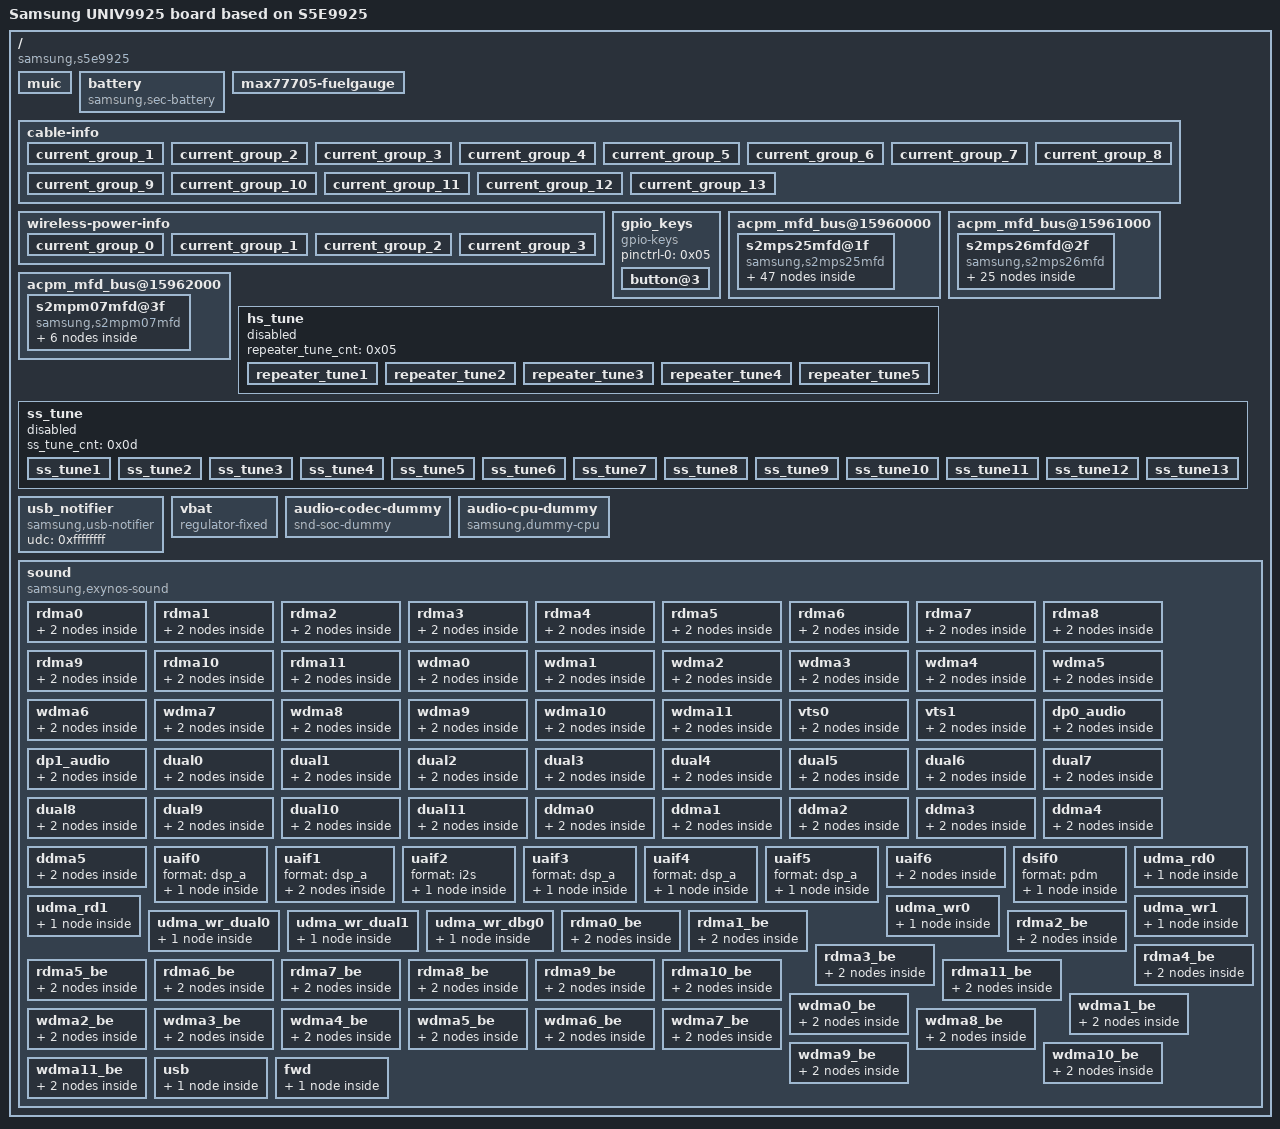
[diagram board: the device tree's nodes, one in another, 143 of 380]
/dts-v1/;

/ {
	compatible = "samsung,s5e9925\0samsung,UNIV9925";
	board_id = <0x01>;
	board_rev = <0x1b>;

	fragment@muic {
		target-path = "/";

		__overlay__ {

			muic {
				status = "okay";
				muic,support-list = "TA\0USB\0CDP\0JIG UART OFF\0JIG UART OFF/VB\0JIG UART ON\0JIG UART ON/VB\0JIG USB OFF\0JIG USB ON\0OTG\0Unofficial TA\0DCD Timeout\0AFC Charger";
			};
		};
	};

	fragment@0 {
		target = <0xffffffff>;

		__overlay__ {

			max77705-irq {
				samsung,pins = "gpa0-0";
				samsung,pin-function = <0x0f>;
				samsung,pin-pud = <0x00>;
				samsung,pin-drv = <0x00>;
				phandle = <0x02>;
			};
		};
	};

	fragment@1 {
		target = <0xffffffff>;

		__overlay__ {

			hsi2c2-bus-max77705 {
				samsung,pins = "gpm0-0\0gpm0-1";
				samsung,pin-function = <0x02>;
				samsung,pin-pud = <0x00>;
				samsung,pin-drv = <0x00>;
				samsung,pin-con-pdn = <0x03>;
				samsung,pin-pud-pdn = <0x00>;
				phandle = <0x01>;
			};
		};
	};

	fragment@2 {
		target = <0xffffffff>;

		__overlay__ {
			#address-cells = <0x01>;
			#size-cells = <0x00>;
			status = "okay";
			pinctrl-0 = <0x01>;

			max77705@66 {
				compatible = "maxim,max77705";
				pinctrl-names = "default";
				pinctrl-0 = <0x02>;
				reg = <0x66>;
				max77705,irq-gpio = <0xffffffff 0x00 0x01>;
				max77705,wakeup;
				max77705,fw_product_id = <0x03>;
				max77705,support-audio;
				phandle = <0x1d>;

				max77705_pdic {
					status = "okay";
					compatible = "maxim,max77705_pdic";
					support_pd_role_swap;
				};
			};
		};
	};

	fragment@battery {
		target-path = "/";

		__overlay__ {

			battery {
				status = "okay";
				compatible = "samsung,sec-battery";
				pinctrl-names = "default";
				battery,vendor = "Battery";
				battery,charger_name = "max77705-charger";
				battery,fuelgauge_name = "max77705-fuelgauge";
				battery,technology = <0x02>;
				battery,fgsrc_switch_name = "max77705-charger";
				battery,batt_data_version = <0x03>;
				battery,chip_vendor = "LSI";
				battery,temp_adc_type = <0x01>;
				battery,temp_check_type = <0x03>;
				battery,usb_temp_check_type = <0x03>;
				battery,chg_temp_check_type = <0x03>;
				battery,wpc_temp_check_type = <0x03>;
				battery,dchg_temp_check_type = <0x03>;
				battery,thermal_source = <0x02>;
				battery,usb_thermal_source = <0x02>;
				battery,chg_thermal_source = <0x02>;
				battery,wpc_thermal_source = <0x02>;
				battery,dchg_thermal_source = <0x03>;
				battery,polling_time = <0x0a 0x1e 0x1e 0x1e 0xe10>;
				battery,temp_table_adc = <0x137 0x168 0x1a0 0x1e3 0x232 0x28f 0x2fb 0x379 0x409 0x48a 0x53c 0x603 0x6da 0x7ba 0x8ab 0x99b 0xa8a 0xb6a 0xc33 0xce8 0xd89 0xe04 0xe5f>;
				battery,temp_table_data = <0x384 0x352 0x320 0x2ee 0x2bc 0x28a 0x258 0x226 0x1f4 0x1c2 0x190 0x15e 0x12c 0xfa 0xc8 0x96 0x64 0x32 0x00 0xffffffce 0xffffff9c 0xffffff6a 0xffffff38>;
				battery,usb_temp_table_adc = <0x10c 0x146 0x180 0x1c5 0x214 0x270 0x2dd 0x35b 0x3e9 0x489 0x54c 0x616 0x6ee 0x7d0 0x8bb 0x9a6 0xa84 0xb61 0xc1c 0xcce 0xd67 0xdd3 0xe51>;
				battery,usb_temp_table_data = <0x384 0x352 0x320 0x2ee 0x2bc 0x28a 0x258 0x226 0x1f4 0x1c2 0x190 0x15e 0x12c 0xfa 0xc8 0x96 0x64 0x32 0x00 0xffffffce 0xffffff9c 0xffffff6a 0xffffff38>;
				battery,chg_temp_table_adc = <0xdd 0x114 0x14b 0x18e 0x1da 0x234 0x29b 0x31a 0x3a7 0x448 0x505 0x5d1 0x6af 0x799 0x889 0x97c 0xa69 0xb4f 0xc1f 0xcdb 0xd76 0xdf0 0xe75>;
				battery,chg_temp_table_data = <0x384 0x352 0x320 0x2ee 0x2bc 0x28a 0x258 0x226 0x1f4 0x1c2 0x190 0x15e 0x12c 0xfa 0xc8 0x96 0x64 0x32 0x00 0xffffffce 0xffffff9c 0xffffff6a 0xffffff38>;
				battery,wpc_temp_table_adc = <0x137 0x168 0x1a0 0x1e3 0x232 0x28f 0x2fb 0x379 0x409 0x48a 0x53c 0x603 0x6da 0x7ba 0x8ab 0x99b 0xa8a 0xb6a 0xc33 0xce8 0xd89 0xe04 0xe5f>;
				battery,wpc_temp_table_data = <0x384 0x352 0x320 0x2ee 0x2bc 0x28a 0x258 0x226 0x1f4 0x1c2 0x190 0x15e 0x12c 0xfa 0xc8 0x96 0x64 0x32 0x00 0xffffffce 0xffffff9c 0xffffff6a 0xffffff38>;
				battery,dchg_temp_table_adc = <0x15c3c 0x1b7e0 0x21384 0x2817c 0x301c8 0x39d92 0x454da 0x527a0 0x61f0e 0x731fa 0x86064 0x9c5ca 0xb3d84 0xcd9e6 0xe7648 0x1024fe 0x11c160 0x134b6e 0x14b9fe 0x15fabc 0x170da8 0x17f2c2 0x18b334>;
				battery,dchg_temp_table_data = <0x384 0x352 0x320 0x2ee 0x2bc 0x28a 0x258 0x226 0x1f4 0x1c2 0x190 0x15e 0x12c 0xfa 0xc8 0x96 0x64 0x32 0x00 0xffffffce 0xffffff9c 0xffffff6a 0xffffff38>;
				battery,wireless_cc_cv = <0x55>;
				battery,wpc_cc_cv_vout = <0x157c>;
				battery,wpc_cv_call_vout = <0x1388>;
				battery,wpc_cc_call_vout = <0x1388>;
				battery,wpc_det = <0xffffffff 0x00 0x00>;
				battery,wpc_int = <0xffffffff 0x01 0x00>;
				battery,hv_vout_wa = <0x41>;
				battery,adc_check_count = <0x05>;
				battery,cable_check_type = <0x04>;
				battery,cable_source_type = <0x01>;
				battery,polling_type = <0x01>;
				battery,monitor_initial_count = <0x00>;
				battery,battery_check_type = <0x00>;
				battery,check_count = <0x00>;
				battery,check_adc_max = <0x5a0>;
				battery,check_adc_min = <0x00>;
				battery,ovp_uvlo_check_type = <0x03>;
				battery,temp_check_count = <0x01>;
				battery,overheatlimit_threshold = <0x2bc>;
				battery,overheatlimit_recovery = <0x2a8>;
				battery,wire_warm_overheat_thresh = <0x1f4>;
				battery,wire_normal_warm_thresh = <0x19a>;
				battery,wire_cool1_normal_thresh = <0xb4>;
				battery,wire_cool2_cool1_thresh = <0x96>;
				battery,wire_cool3_cool2_thresh = <0x32>;
				battery,wire_cold_cool3_thresh = <0x00>;
				battery,wireless_warm_overheat_thresh = <0x1c2>;
				battery,wireless_normal_warm_thresh = <0x19a>;
				battery,wireless_cool1_normal_thresh = <0xb4>;
				battery,wireless_cool2_cool1_thresh = <0x96>;
				battery,wireless_cool3_cool2_thresh = <0x32>;
				battery,wireless_cold_cool3_thresh = <0x00>;
				battery,wire_warm_current = <0x625>;
				battery,wire_cool1_current = <0xc4a>;
				battery,wire_cool2_current = <0x418>;
				battery,wire_cool3_current = <0x1b5>;
				battery,wireless_warm_current = <0x418>;
				battery,wireless_cool1_current = <0xc4a>;
				battery,wireless_cool2_current = <0x418>;
				battery,wireless_cool3_current = <0x1b5>;
				battery,tx_high_threshold = <0x1c2>;
				battery,tx_high_recovery = <0x190>;
				battery,tx_low_threshold = <0x00>;
				battery,tx_low_recovery = <0x32>;
				battery,full_check_type = <0x02>;
				battery,full_check_type_2nd = <0x02>;
				battery,full_check_count = <0x01>;
				battery,chg_gpio_full_check = <0x00>;
				battery,chg_polarity_full_check = <0x01>;
				battery,chg_high_temp = <0x1d6>;
				battery,chg_high_temp_recovery = <0x1c2>;
				battery,dchg_high_temp = <0x208>;
				battery,dchg_high_temp_recovery = <0x1cc>;
				battery,dchg_high_batt_temp = <0x190>;
				battery,dchg_high_batt_temp_recovery = <0x17c>;
				battery,chg_input_limit_current = <0x3e8>;
				battery,chg_charging_limit_current = <0x76c>;
				battery,dchg_input_limit_current = <0x3e8>;
				battery,dchg_charging_limit_current = <0x7d0>;
				battery,charging_limit_by_tx_check = <0x01>;
				battery,charging_limit_current_by_tx = <0x4b0>;
				battery,wpc_temp_control_source = <0x01>;
				battery,wpc_high_temp = <0x190>;
				battery,wpc_high_temp_recovery = <0x17c>;
				battery,wpc_input_limit_current = <0x258>;
				battery,wpc_charging_limit_current = <0x3e8>;
				battery,wpc_temp_lcd_on_control_source = <0x01>;
				battery,wpc_lcd_on_high_temp = <0x190>;
				battery,wpc_lcd_on_high_temp_rec = <0x17c>;
				battery,wpc_lcd_on_input_limit_current = <0x1c2>;
				battery,wpc_store_high_temp = <0x168>;
				battery,wpc_store_high_temp_recovery = <0x154>;
				battery,wpc_store_lcd_on_high_temp = <0x168>;
				battery,wpc_store_lcd_on_high_temp_rec = <0x12c>;
				battery,wpc_store_lcd_on_charging_limit_current = <0x190>;
				battery,sleep_mode_limit_current = <0x320>;
				battery,wc_full_input_limit_current = <0x64>;
				battery,mix_high_temp = <0x1a4>;
				battery,mix_high_chg_temp = <0x1f4>;
				battery,mix_high_dc_temp = <0x244>;
				battery,mix_high_temp_recovery = <0x186>;
				battery,full_condition_type = <0x09>;
				battery,full_condition_soc = <0x5d>;
				battery,full_condition_vcell = <0x10ea>;
				battery,recharge_check_count = <0x01>;
				battery,recharge_condition_type = <0x04>;
				battery,recharge_condition_soc = <0x62>;
				battery,recharge_condition_vcell = <0x10d6>;
				battery,charging_total_time = <0x3840>;
				battery,hv_charging_total_time = <0x2a30>;
				battery,normal_charging_total_time = <0x4650>;
				battery,usb_charging_total_time = <0x8ca0>;
				battery,recharging_total_time = <0x1518>;
				battery,charging_reset_time = <0x00>;
				battery,chg_float_voltage = <0x111c>;
				battery,chg_ocp_current = <0x1838>;
				battery,chg_ocp_dtc = <0x64>;
				battery,swelling_drop_float_voltage = <0x1036>;
				battery,swelling_high_rechg_voltage = <0xfa0>;
				battery,swelling_low_rechg_voltage = <0xfa0>;
				battery,wa_float_voltage = <0xfd2>;
				battery,siop_event_check_type = <0x01>;
				battery,siop_call_cv_current = <0x12c>;
				battery,siop_call_cc_current = <0x12c>;
				battery,siop_input_limit_current = <0x4b0>;
				battery,siop_charging_limit_current = <0x3e8>;
				battery,siop_hv_input_limit_current = <0x2bc>;
				battery,siop_hv_charging_limit_current = <0x3e8>;
				battery,siop_apdo_input_limit_current = <0x4b0>;
				battery,siop_apdo_charging_limit_current = <0x7d0>;
				battery,siop_wireless_input_limit_current = <0x258>;
				battery,siop_wireless_charging_limit_current = <0x352>;
				battery,siop_hv_wireless_input_limit_current = <0x2bc>;
				battery,siop_hv_wireless_charging_limit_current = <0x352>;
				battery,siop_store_hv_wireless_input_limit_current = <0x1c2>;
				battery,store_mode_buckoff;
				battery,ttf_hv_charge_current = <0xbb8>;
				battery,ttf_hv_wireless_charge_current = <0x5dc>;
				battery,ttf_wireless_charge_current = <0x384>;
				battery,ttf_dc25_charge_current = <0x1068>;
				battery,ttf_dc45_charge_current = <0x1770>;
				battery,rp_current_rp1 = <0x1f4>;
				battery,rp_current_rp2 = <0x5dc>;
				battery,rp_current_rp3 = <0xbb8>;
				battery,rp_current_rdu_rp3 = <0x834>;
				battery,rp_current_abnormal_rp3 = <0x708>;
				battery,pd_charging_charge_power = <0x3a98>;
				battery,max_charging_current = <0xc4e>;
				battery,max_charging_charge_power = <0x61a8>;
				battery,battery_full_capacity = <0x1194>;
				battery,age_data = <0x00 0x111c 0x10d6 0x10ea 0x5d 0x12c 0x1108 0x10c2 0x10d6 0x5c 0x190 0x10f4 0x10ae 0x10c2 0x5b 0x2bc 0x10e0 0x109a 0x10ae 0x5a 0x3e8 0x10ae 0x1068 0x107c 0x59>;
				battery,health_condition = <0x384 0x4b 0x4b0 0x41 0x5dc 0x37>;
				battery,step_charging_type = <0x00>;
				battery,dc_step_chg_type = <0x6b>;
				battery,dc_step_chg_charge_power = <0x55f0>;
				battery,dc_step_chg_step = <0x03>;
				battery,dc_step_chg_step_2nd = <0x00>;
				battery,dc_step_chg_cond_vol = <0x101d 0x109a 0x111c>;
				battery,dc_step_chg_cond_iin = <0x7ee 0x721 0x00>;
				battery,dc_step_chg_val_vfloat = <0x101d 0x109a 0x111c>;
				battery,dc_step_chg_val_iout = <0x14aa 0xffa 0xe56>;
				battery,dc_step_chg_cond_soc = <0x14 0x32 0x64 0x14 0x32 0x64 0x14 0x32 0x64 0x14 0x32 0x64 0x14 0x32 0x64>;
				battery,pre_afc_input_current = <0x1f4>;
				battery,pre_afc_work_delay = <0x2710>;
				battery,prepare_ta_delay = <0x00>;
				battery,max_input_voltage = <0x2328>;
				battery,max_input_current = <0xbb8>;
				battery,enable_sysovlo_irq;
				battery,enable_noise_wa;
				battery,dis_auto_shipmode_temp_ctrl;
				battery,standard_curr = <0xc4e>;
				battery,expired_time = <0x2a30>;
				battery,recharging_expired_time = <0x1518>;
				battery,cisd_max_voltage_thr = <0x114e>;
				battery,cisd_alg_index = <0x08>;
				battery,ignore_cisd_index = <0x00 0x280>;
				battery,ignore_cisd_index_d = <0x00 0x50>;
				battery,tx_stop_capacity = <0x1e>;
				battery,tx_minduty_default = <0x14>;
				battery,tx_minduty_5V = <0x32>;
				battery,tx_uno_iout = <0x5dc>;
				battery,tx_mfc_iout_gear = <0x5dc>;
				battery,tx_mfc_iout_phone = <0x44c>;
				battery,tx_mfc_iout_phone_5v = <0x12c>;
				battery,tx_mfc_iout_lcd_on = <0x384>;
				#io-channel-cells = <0x05>;
				phandle = <0x1e>;
			};

			max77705-fuelgauge {
				status = "okay";
				fuelgauge,fuel_alert_soc = <0xffffffff>;
				fuelgauge,jig_gpio = <0xffffffff 0x06 0x01>;
				fuelgauge,jig_low_active;
				fuelgauge,capacity_max = <0x3e8>;
				fuelgauge,capacity_max_margin = <0x12c>;
				fuelgauge,capacity_min = <0x00>;
				fuelgauge,capacity_calculation_type = <0x1c>;
				fuelgauge,repeated_fuelalert;
				fuelgauge,using_temp_compensation;
				fuelgauge,low_temp_limit = <0x64>;
				fuelgauge,using_hw_vempty;
				fuelgauge,v_empty = <0xa7e2>;
				fuelgauge,v_empty_origin = <0x7d54>;
				fuelgauge,sw_v_empty_voltage = <0xc80>;
				fuelgauge,sw_v_empty_voltage_cisd = <0xc1c>;
				fuelgauge,sw_v_empty_recover_voltage = <0xd98>;
				fuelgauge,qrtable20 = <0xf00>;
				fuelgauge,qrtable30 = <0xb00>;
				fuelgauge,fg_resistor = <0x02>;
				fuelgauge,capacity = <0xfef>;
				fuelgauge,discharge_temp_threshold = <0x258>;
				fuelgauge,discharge_volt_threshold = <0x1068>;
				fuelgauge,ttf_capacity = <0xfd2>;
				fuelgauge,cv_data = <0xe95 0x348 0x5b6 0xe6a 0x34a 0x5ac 0xe20 0x34f 0x598 0xdf7 0x351 0x58d 0xda2 0x353 0x583 0xd7c 0x355 0x579 0xd31 0x35a 0x565 0xd0e 0x35c 0x55a 0xccb 0x35e 0x550 0xc9c 0x360 0x546 0xc3d 0x362 0x53c 0xbfb 0x368 0x51d 0xbcb 0x36a 0x513 0xb71 0x36f 0x4f4 0xb50 0x371 0x4ea 0xb1b 0x373 0x4df 0xae8 0x375 0x4d5 0xac2 0x377 0x4cb 0xa87 0x37c 0x4ac 0xa64 0x37d 0x4a2 0xa41 0x37f 0x498 0xa14 0x381 0x48d 0x9e3 0x382 0x483 0x9bc 0x386 0x46f 0x992 0x387 0x465 0x96a 0x389 0x45a 0x92c 0x38c 0x446 0x8f8 0x38d 0x43c 0x8d7 0x38e 0x431 0x8a6 0x393 0x413 0x886 0x394 0x408 0x863 0x397 0x3f4 0x837 0x398 0x3ea 0x803 0x39a 0x3df 0x7e3 0x39c 0x3cb 0x7bd 0x39f 0x3b6 0x79c 0x3a0 0x3ac 0x777 0x3a2 0x398 0x757 0x3a4 0x38d 0x72a 0x3a5 0x383 0x703 0x3a7 0x36f 0x6e1 0x3aa 0x350 0x6ba 0x3ae 0x331 0x699 0x3b0 0x31d 0x671 0x3b2 0x308 0x638 0x3b4 0x2f4 0x5fc 0x3b6 0x2df 0x5d5 0x3ba 0x2b6 0x5b6 0x3bb 0x2ac 0x582 0x3be 0x283 0x552 0x3bf 0x279 0x53a 0x3c0 0x26f 0x50b 0x3c4 0x23c 0x4f0 0x3c8 0x213 0x4d5 0x3c8 0x208 0x4bd 0x3c9 0x1fe 0x491 0x3ce 0x1c1 0x467 0x3cf 0x1b6 0x451 0x3cf 0x1ac 0x431 0x3d4 0x165 0x419 0x3d6 0x146 0x3f2 0x3d7 0x131 0x3e1 0x3d8 0x127 0x3cc 0x3da 0x108 0x3bb 0x3dc 0xdf 0x3a4 0x3de 0xcb 0x371 0x3de 0xc1 0x360 0x3e4 0xac 0x2f9 0x3e8 0x7b 0x2c6 0x3e8 0x71 0x2b0 0x3e8 0x67 0x29c 0x3e8 0x33 0x292 0x3e8 0x1f 0x287 0x3e8 0x00>;
				phandle = <0x1f>;
			};

			cable-info {
				default_input_current = <0x708>;
				default_charging_current = <0x834>;
				full_check_current_1st = <0x28f>;
				full_check_current_2nd = <0xda>;
				phandle = <0x20>;

				current_group_1 {
					cable_number = <0x02 0x13 0x15 0x16 0x17 0x1e>;
					input_current = <0x1f4>;
					charging_current = <0x1f4>;
				};

				current_group_2 {
					cable_number = <0x19 0x1f>;
					input_current = <0x3e8>;
					charging_current = <0x3e8>;
				};

				current_group_3 {
					cable_number = <0x05 0x20>;
					input_current = <0x5dc>;
					charging_current = <0x5dc>;
				};

				current_group_4 {
					cable_number = <0x06 0x07 0x08>;
					input_current = <0x672>;
					charging_current = <0xc4e>;
				};

				current_group_5 {
					cable_number = <0x09>;
					input_current = <0x672>;
					charging_current = <0xc4e>;
				};

				current_group_6 {
					cable_number = <0x0a 0x0c 0x0f 0x1b 0x21 0x23>;
					input_current = <0x320>;
					charging_current = <0xc4e>;
				};

				current_group_7 {
					cable_number = <0x0d>;
					input_current = <0x2bc>;
					charging_current = <0xc4e>;
				};

				current_group_8 {
					cable_number = <0x18>;
					input_current = <0x3e8>;
					charging_current = <0x1c2>;
				};

				current_group_9 {
					cable_number = <0x1a>;
					input_current = <0x7d0>;
					charging_current = <0x708>;
				};

				current_group_10 {
					cable_number = <0x0b 0x0e 0x10 0x1c>;
					input_current = <0x2ee>;
					charging_current = <0xc4e>;
				};

				current_group_11 {
					cable_number = <0x1d 0x24 0x25>;
					input_current = <0x1f4>;
					charging_current = <0x578>;
				};

				current_group_12 {
					cable_number = <0x01 0x04>;
					input_current = <0x1db>;
					charging_current = <0x226>;
				};

				current_group_13 {
					cable_number = <0x22>;
					input_current = <0x1f4>;
					charging_current = <0xc4e>;
				};
			};

			wireless-power-info {
				phandle = <0x21>;

				current_group_0 {
					wireless_power_class = <0x01>;
					vout = <0x157c>;
					input_current_limit = <0x320>;
					fast_charging_current = <0xc4e>;
					ttf_charge_current = <0x384>;
					rx_power = <0x1194>;
				};

				current_group_1 {
					wireless_power_class = <0x02>;
					vout = <0x2710>;
					input_current_limit = <0x2ee>;
					fast_charging_current = <0xc4e>;
					ttf_charge_current = <0x5dc>;
					rx_power = <0x1d4c>;
				};

				current_group_2 {
					wireless_power_class = <0x02>;
					vout = <0x2af8>;
					input_current_limit = <0x44c>;
					fast_charging_current = <0xc4e>;
					ttf_charge_current = <0x834>;
					rx_power = <0x2ee0>;
				};

				current_group_3 {
					wireless_power_class = <0x02>;
					vout = <0x2af8>;
					input_current_limit = <0x514>;
					fast_charging_current = <0xc4e>;
					ttf_charge_current = <0x8fc>;
					rx_power = <0x36b0>;
				};
			};
		};
	};

	fragment@3 {
		target = <0xffffffff>;

		__overlay__ {

			wpc-en {
				samsung,pins = "gpb5-1";
				samsung,pin-function = <0x01>;
				samsung,pin-pud = <0x00>;
				samsung,pin-drv = <0x00>;
				phandle = <0x22>;
			};
		};
	};

	fragment@4 {
		target = <0xffffffff>;

		__overlay__ {

			dc-cpen {
				samsung,pins = "gpm19-0";
				samsung,pin-function = <0x01>;
				samsung,pin-pud = <0x00>;
				samsung,pin-drv = <0x00>;
				phandle = <0x23>;
			};
		};
	};

	fragment@5 {
		target = <0xffffffff>;

		__overlay__ {

			wpc-det {
				samsung,pins = "gpa2-0";
				samsung,pin-function = <0x0f>;
				samsung,pin-pud = <0x00>;
				samsung,pin-drv = <0x00>;
				phandle = <0x03>;
			};

			wpc-int {
				samsung,pins = "gpa3-1";
				samsung,pin-function = <0x0f>;
				samsung,pin-pud = <0x00>;
				samsung,pin-drv = <0x00>;
				phandle = <0x04>;
			};
		};
	};

	fragment@6 {
		target = <0xffffffff>;

		__overlay__ {

			mfc-i2c {
				samsung,pins = "gpp1-2\0gpp1-3";
				samsung,pin-function = <0x02>;
				samsung,pin-pud = <0x00>;
				samsung,pin-drv = <0x00>;
				samsung,pin-con-pdn = <0x03>;
				samsung,pin-pud-pdn = <0x00>;
				phandle = <0x24>;
			};
		};
	};

	fragment@7 {
		target = <0xffffffff>;

		__overlay__ {
			#address-cells = <0x01>;
			#size-cells = <0x00>;
			status = "disabled";
			pinctrl-names = "default";
			samsung,stop-after-trans;
			samsung,stand-mode;
			clock-frequency = <0x186a0>;

			mfc-charger@3b {
				compatible = "idt,mfc-charger";
				reg = <0x3b>;
				status = "okay";
				pinctrl-names = "default";
				pinctrl-0 = <0x03 0x04>;
				battery,wpc_int = <0xffffffff 0x07 0x00>;
				battery,wpc_det = <0xffffffff 0x05 0x00>;
				battery,mst_pwr_en = <0xffffffff 0x00 0x00>;
				battery,charger_name = "max77705-charger";
				battery,fuelgauge_name = "max77705-fuelgauge";
				battery,wc_cover_rpp = <0x44>;
				battery,phone_fod_threshold = <0x3b>;
				battery,wireless20_vout_list = <0x09 0x09 0x09>;
				battery,wireless20_vrect_list = <0x0a 0x0b 0x0b>;
				battery,wireless20_max_power_list = <0x02 0x03 0x03>;

				fod_list {
					count = <0x02>;

					pad_0x00 {
						flag = <0x111>;
						cc = <0x96 0x40 0x8e 0x35 0x96 0x26 0x96 0x22 0x9b 0x12 0x9c 0x11>;
						cv = <0x96 0x5e 0x8e 0x53 0x96 0x44 0x96 0x40 0x9b 0x30 0x9c 0x2f>;
						full = <0xff 0x7f 0xff 0x7f 0xff 0x7f 0xff 0x7f 0xff 0x7f 0xff 0x7f>;
					};

					pad_0x30 {
						flag = <0x321>;
						cc = <0x96 0x02 0x8e 0xfffffffa 0x96 0xffffffec 0x96 0xffffffe4 0xa5 0xb9 0x9c 0xffffffd9>;
					};
				};
			};
		};
	};

	fragment@8 {
		target = <0xffffffff>;

		__overlay__ {

			dsim-modes {

				1440x3200@60 {
					mode-name = "1440x3200@60";
					pmsk = <0x05 0x59 0x00 0xac00 0x00 0x00 0x00 0x00 0x00 0x00 0x00 0x00 0x00 0x00>;
					hs-clk = <0x552>;
					esc-clk = <0x14>;
					cmd_underrun_cnt = <0x1e9a>;
				};

				1080x2400@60 {
					mode-name = "1080x2400@60";
					pmsk = <0x05 0x59 0x00 0xac00 0x00 0x00 0x00 0x00 0x00 0x00 0x00 0x00 0x00 0x00>;
					hs-clk = <0x552>;
					esc-clk = <0x14>;
					cmd_underrun_cnt = <0x2879>;
				};

				1080x2340@120 {
					mode-name = "1080x2340@120";
					pmsk = <0x05 0x59 0x00 0xac00 0x00 0x00 0x00 0x00 0x00 0x00 0x00 0x00 0x00 0x00>;
					hs-clk = <0x552>;
					esc-clk = <0x14>;
					cmd_underrun_cnt = <0xd5b>;
				};

				1080x2340@60 {
					mode-name = "1080x2340@60";
					pmsk = <0x05 0x59 0x00 0xac00 0x00 0x00 0x00 0x00 0x00 0x00 0x00 0x00 0x00 0x00>;
					hs-clk = <0x552>;
					esc-clk = <0x14>;
					cmd_underrun_cnt = <0x28ca>;
				};

				1080x2400@120 {
					mode-name = "1080x2400@120";
					pmsk = <0x05 0x59 0x00 0xac00 0x00 0x00 0x00 0x00 0x00 0x00 0x00 0x00 0x00 0x00>;
					hs-clk = <0x552>;
					esc-clk = <0x14>;
					cmd_underrun_cnt = <0xd09>;
				};

				720x1600@60 {
					mode-name = "720x1600@60";
					pmsk = <0x05 0x59 0x00 0xac00 0x00 0x00 0x00 0x00 0x00 0x00 0x00 0x00 0x00 0x00>;
					hs-clk = <0x552>;
					esc-clk = <0x14>;
					cmd_underrun_cnt = <0x30ab>;
				};

				720x1600@120 {
					mode-name = "720x1600@120";
					pmsk = <0x05 0x59 0x00 0xac00 0x00 0x00 0x00 0x00 0x00 0x00 0x00 0x00 0x00 0x00>;
					hs-clk = <0x552>;
					esc-clk = <0x14>;
					cmd_underrun_cnt = <0x153b>;
				};

				640x480 {
					mode-name = "640x480";
					pmsk = <0x02 0x8a 0x01 0x89d9 0x00 0x00 0x00 0x00 0x00 0x00 0x00 0x00 0x00 0x00>;
					hs-clk = <0x37e>;
					esc-clk = <0x14>;
					cmd_underrun_cnt = <0x144b>;
				};
			};
		};
	};

	fragment@model {
		target-path = "/";

		__overlay__ {
			#address-cells = <0x02>;
			#size-cells = <0x01>;
			model = "Samsung UNIV9925 board based on S5E9925";

			gpio_keys {
				status = "okay";
				compatible = "gpio-keys";
				pinctrl-names = "default";
				pinctrl-0 = <0x05>;

				button@3 {
					label = "gpio-keys: KEY_VOLUMEUP";
					linux,code = <0x73>;
					gpios = <0xffffffff 0x00 0x0f>;
				};
			};

			acpm_mfd_bus@15960000 {
				status = "okay";
				#address-cells = <0x01>;
				#size-cells = <0x00>;

				s2mps25mfd@1f {
					compatible = "samsung,s2mps25mfd";
					acpm-ipc-channel = <0x02>;
					acpm-speedy-channel = <0x00>;
					s2mps25,wakeup = "enabled";
					reg = <0x1f>;
					interrupts = <0x00 0x25 0x04>;
					interrupt-parent = <0xffffffff>;
					pinctrl-names = "default";
					pinctrl-0 = <0x06 0x07>;
					gpios = <0xffffffff 0x04 0x00>;
					wtsr_en = "enabled";
					smpl_en = "enabled";
					wtsr_timer_val = <0x03>;
					smpl_timer_val = <0x04>;
					check_jigon = <0x00>;
					init_time,sec = <0x00>;
					init_time,min = <0x00>;
					init_time,hour = <0x0c>;
					init_time,mday = <0x01>;
					init_time,mon = <0x00>;
					init_time,year = <0x79>;
					init_time,wday = <0x05>;
					smpl_warn_en = <0x01>;
					adc_mode = <0x01>;

					s2mps25-gpadc {
						#io-channel-cells = <0x01>;
						io-channel-ranges;
						acpm-ipc-channel = <0x0b>;
						phandle = <0x25>;
					};

					s2mps25-keys {

						button@1 {
							label = "pmic-keys: KEY_POWER";
							linux,code = <0x74>;
							wakeup;
						};

						button@2 {
							label = "pmic-keys: KEY_VOLUMEDOWN";
							linux,code = <0x72>;
						};
					};

					regulators {

						BUCK1 {
							regulator-name = "vdd2h_mem";
							regulator-min-microvolt = <0x61a80>;
							regulator-max-microvolt = <0x13d620>;
							regulator-always-on;
							regulator-ramp-delay = <0x1770>;
							regulator-initial-mode = <0x03>;
							phandle = <0x26>;
						};

						BUCK2 {
							regulator-name = "vddq_mem";
							regulator-min-microvolt = <0x55730>;
							regulator-max-microvolt = <0xaae60>;
							regulator-ramp-delay = <0x1770>;
							regulator-initial-mode = <0x01>;
							regulator-always-on;
							phandle = <0x27>;
						};

						BUCK3 {
							regulator-name = "vdd_int";
							regulator-min-microvolt = <0x61a80>;
							regulator-max-microvolt = <0x13d620>;
							regulator-ramp-delay = <0x1770>;
							regulator-initial-mode = <0x01>;
							regulator-always-on;
							phandle = <0x28>;
						};

						BUCK4 {
							regulator-name = "vdd_g3d_ph1";
							regulator-min-microvolt = <0x61a80>;
							regulator-max-microvolt = <0x13d620>;
							regulator-ramp-delay = <0x1770>;
							regulator-initial-mode = <0x01>;
							regulator-always-on;
							phandle = <0x29>;
						};

						BUCK5 {
							regulator-name = "vdd_g3d_ph2";
							regulator-min-microvolt = <0x61a80>;
							regulator-max-microvolt = <0x13d620>;
							regulator-ramp-delay = <0x1770>;
							regulator-initial-mode = <0x01>;
							regulator-always-on;
							phandle = <0x2a>;
						};

						BUCK6 {
							regulator-name = "vdd_g3d_ph3";
							regulator-min-microvolt = <0x61a80>;
							regulator-max-microvolt = <0x13d620>;
							regulator-ramp-delay = <0x1770>;
							regulator-initial-mode = <0x01>;
							regulator-always-on;
							phandle = <0x2b>;
						};

						BUCK7 {
							regulator-name = "vdd_cpucl0_lit";
							regulator-min-microvolt = <0x61a80>;
							regulator-max-microvolt = <0x13d620>;
							regulator-ramp-delay = <0x1770>;
							regulator-initial-mode = <0x01>;
							regulator-always-on;
							phandle = <0x2c>;
						};

						BUCK8 {
							regulator-name = "vdd_cpucl1_big_mid_ph1";
							regulator-min-microvolt = <0x61a80>;
							regulator-max-microvolt = <0x13d620>;
							regulator-ramp-delay = <0x1770>;
							regulator-initial-mode = <0x01>;
							regulator-always-on;
							phandle = <0x2d>;
						};

						BUCK9 {
							regulator-name = "vdd_cpucl1_big_mid_ph2";
							regulator-min-microvolt = <0x61a80>;
							regulator-max-microvolt = <0x13d620>;
							regulator-ramp-delay = <0x1770>;
							regulator-initial-mode = <0x01>;
							regulator-always-on;
							phandle = <0x2e>;
						};

						BUCK10 {
							regulator-name = "vdd_cpucl1_big_mid_ph3";
							regulator-min-microvolt = <0x61a80>;
							regulator-max-microvolt = <0x13d620>;
							regulator-ramp-delay = <0x1770>;
							regulator-initial-mode = <0x01>;
							regulator-always-on;
							phandle = <0x2f>;
						};

						BUCK_SR1 {
							regulator-name = "vdd_lldo2";
							regulator-min-microvolt = <0x927c0>;
							regulator-max-microvolt = <0x149970>;
							regulator-always-on;
							regulator-ramp-delay = <0x1770>;
							regulator-initial-mode = <0x03>;
							phandle = <0x30>;
						};

						BUCK_SR2 {
							regulator-name = "vdd_mldo";
							regulator-min-microvolt = <0x1ab3f0>;
							regulator-max-microvolt = <0x1e8480>;
							regulator-always-on;
							regulator-ramp-delay = <0x1770>;
							regulator-initial-mode = <0x03>;
							phandle = <0x31>;
						};

						BUCK_SR3 {
							regulator-name = "vdd_lldo1";
							regulator-min-microvolt = <0x927c0>;
							regulator-max-microvolt = <0x149970>;
							regulator-always-on;
							regulator-ramp-delay = <0x1770>;
							regulator-initial-mode = <0x03>;
							phandle = <0x32>;
						};

						LDO1 {
							regulator-name = "vdd_ldo1";
							regulator-min-microvolt = <0x61a80>;
							regulator-max-microvolt = <0x13d620>;
							regulator-always-on;
							regulator-ramp-delay = <0x2ee0>;
							regulator-initial-mode = <0x03>;
							phandle = <0x33>;
						};

						LDO2 {
							regulator-name = "vdd_ldo2";
							regulator-min-microvolt = <0x61a80>;
							regulator-max-microvolt = <0x13d620>;
							regulator-always-on;
							regulator-ramp-delay = <0x2ee0>;
							regulator-initial-mode = <0x03>;
							phandle = <0x34>;
						};

						LDO3 {
							regulator-name = "vdd_ldo3";
							regulator-min-microvolt = <0x1b7740>;
							regulator-max-microvolt = <0x1cfde0>;
							regulator-always-on;
							regulator-ramp-delay = <0x2ee0>;
							regulator-initial-mode = <0x03>;
							phandle = <0x0c>;
						};

						LDO4 {
							regulator-name = "vdd_ldo4";
							regulator-min-microvolt = <0x61a80>;
							regulator-max-microvolt = <0x13d620>;
							regulator-ramp-delay = <0x2ee0>;
							regulator-initial-mode = <0x01>;
							regulator-always-on;
							phandle = <0x35>;
						};

						LDO5 {
							regulator-name = "vdd075_usb";
							regulator-min-microvolt = <0x61a80>;
							regulator-max-microvolt = <0x13d620>;
							regulator-ramp-delay = <0x2ee0>;
							regulator-initial-mode = <0x03>;
							phandle = <0x10>;
						};

						LDO6 {
							regulator-name = "vdd_ldo6";
							regulator-min-microvolt = <0x61a80>;
							regulator-max-microvolt = <0x13d620>;
							regulator-ramp-delay = <0x2ee0>;
							regulator-initial-mode = <0x01>;
							regulator-always-on;
							phandle = <0x36>;
						};

						LDO7 {
							regulator-name = "vdd12_usb";
							regulator-min-microvolt = <0x61a80>;
							regulator-max-microvolt = <0x13d620>;
							regulator-ramp-delay = <0x2ee0>;
							regulator-initial-mode = <0x03>;
							phandle = <0x11>;
						};

						LDO9 {
							regulator-name = "vdd_ldo9";
							regulator-min-microvolt = <0x61a80>;
							regulator-max-microvolt = <0x13d620>;
							regulator-ramp-delay = <0x2ee0>;
							regulator-initial-mode = <0x01>;
							regulator-always-on;
							phandle = <0x37>;
						};

						LDO10 {
							regulator-name = "AVDD_CSI_1P2";
							regulator-min-microvolt = <0x61a80>;
							regulator-max-microvolt = <0x13d620>;
							regulator-ramp-delay = <0x2ee0>;
							regulator-initial-mode = <0x01>;
							regulator-always-on;
							phandle = <0x38>;
						};

						LDO11 {
							regulator-name = "vdd_ldo11";
							regulator-min-microvolt = <0x61a80>;
							regulator-max-microvolt = <0x13d620>;
							regulator-always-on;
							regulator-ramp-delay = <0x2ee0>;
							regulator-initial-mode = <0x03>;
							phandle = <0x39>;
						};

						LDO12 {
							regulator-name = "vdd_ldo12";
							regulator-min-microvolt = <0x1b7740>;
							regulator-max-microvolt = <0x1cfde0>;
							regulator-always-on;
							regulator-ramp-delay = <0x2ee0>;
							regulator-initial-mode = <0x03>;
							phandle = <0x3a>;
						};

						LDO13 {
							regulator-name = "vdd_ldo13";
							regulator-min-microvolt = <0x1b7740>;
							regulator-max-microvolt = <0x1cfde0>;
							regulator-ramp-delay = <0x2ee0>;
							regulator-initial-mode = <0x01>;
							regulator-always-on;
							phandle = <0x3b>;
						};

						LDO14 {
							regulator-name = "vdd_ldo14";
							regulator-min-microvolt = <0x61a80>;
							regulator-max-microvolt = <0x13d620>;
							regulator-always-on;
							regulator-ramp-delay = <0x2ee0>;
							regulator-initial-mode = <0x03>;
							phandle = <0x3c>;
						};

						LDO15 {
							regulator-name = "vdd_ldo15";
							regulator-min-microvolt = <0x1b7740>;
							regulator-max-microvolt = <0x1cfde0>;
							regulator-always-on;
							regulator-ramp-delay = <0x2ee0>;
							regulator-initial-mode = <0x03>;
							phandle = <0x3d>;
						};

						LDO16 {
							regulator-name = "vdd_ldo16";
							regulator-min-microvolt = <0x1b7740>;
							regulator-max-microvolt = <0x1cfde0>;
							regulator-always-on;
							regulator-ramp-delay = <0x2ee0>;
							regulator-initial-mode = <0x03>;
							phandle = <0x3e>;
						};

						LDO17 {
							regulator-name = "vdd_ldo17";
							regulator-min-microvolt = <0x1b7740>;
							regulator-max-microvolt = <0x1cfde0>;
							regulator-always-on;
							regulator-ramp-delay = <0x2ee0>;
							regulator-initial-mode = <0x03>;
							phandle = <0x3f>;
						};

						LDO18 {
							regulator-name = "vdd_ldo18";
							regulator-min-microvolt = <0x26e8f0>;
							regulator-max-microvolt = <0x26e8f0>;
							regulator-ramp-delay = <0x2ee0>;
							regulator-initial-mode = <0x03>;
							phandle = <0x17>;
						};

						LDO19 {
							regulator-name = "vdd_ldo19";
							regulator-min-microvolt = <0x124f80>;
							regulator-max-microvolt = <0x124f80>;
							regulator-always-on;
							regulator-ramp-delay = <0x2ee0>;
							regulator-initial-mode = <0x03>;
							phandle = <0x18>;
						};

						LDO20 {
							regulator-name = "vdd18_usb";
							regulator-min-microvolt = <0x1b7740>;
							regulator-max-microvolt = <0x1cfde0>;
							regulator-ramp-delay = <0x2ee0>;
							regulator-initial-mode = <0x03>;
							phandle = <0x12>;
						};

						LDO21 {
							regulator-name = "vdd_ldo21";
							regulator-min-microvolt = <0x1b7740>;
							regulator-max-microvolt = <0x1cfde0>;
							regulator-always-on;
							regulator-ramp-delay = <0x2ee0>;
							regulator-initial-mode = <0x03>;
							phandle = <0x40>;
						};

						LDO22 {
							regulator-name = "vdd_ldo22";
							regulator-min-microvolt = <0x1b7740>;
							regulator-max-microvolt = <0x1cfde0>;
							regulator-always-on;
							regulator-ramp-delay = <0x2ee0>;
							regulator-initial-mode = <0x03>;
							phandle = <0x41>;
						};

						LDO23 {
							regulator-name = "vdd_ldo23";
							regulator-min-microvolt = <0x1b7740>;
							regulator-max-microvolt = <0x1cfde0>;
							regulator-always-on;
							regulator-ramp-delay = <0x2ee0>;
							regulator-initial-mode = <0x03>;
							phandle = <0x42>;
						};

						LDO24 {
							regulator-name = "vdd_ldo24";
							regulator-min-microvolt = <0x1b7740>;
							regulator-max-microvolt = <0x1cfde0>;
							regulator-ramp-delay = <0x2ee0>;
							regulator-initial-mode = <0x03>;
							phandle = <0x43>;
						};

						LDO25 {
							regulator-name = "vdd_ldo25";
							regulator-min-microvolt = <0x1b7740>;
							regulator-max-microvolt = <0x1cfde0>;
							regulator-always-on;
							regulator-ramp-delay = <0x2ee0>;
							regulator-initial-mode = <0x03>;
							phandle = <0x44>;
						};

						LDO26 {
							regulator-name = "vdd_ldo26";
							regulator-min-microvolt = <0x1b7740>;
							regulator-max-microvolt = <0x1cfde0>;
							regulator-always-on;
							regulator-ramp-delay = <0x2ee0>;
							regulator-initial-mode = <0x03>;
							phandle = <0x08>;
						};

						LDO27 {
							regulator-name = "vdd_ldo27";
							regulator-min-microvolt = <0x1b7740>;
							regulator-max-microvolt = <0x1cfde0>;
							regulator-always-on;
							regulator-ramp-delay = <0x2ee0>;
							regulator-initial-mode = <0x03>;
							phandle = <0x45>;
						};

						LDO28 {
							regulator-name = "vdd_ldo28";
							regulator-min-microvolt = <0x1b7740>;
							regulator-max-microvolt = <0x1cfde0>;
							regulator-always-on;
							regulator-ramp-delay = <0x2ee0>;
							regulator-initial-mode = <0x03>;
							phandle = <0x1b>;
						};

						LDO29 {
							regulator-name = "vdd_ldo29";
							regulator-min-microvolt = <0x1b7740>;
							regulator-max-microvolt = <0x1cfde0>;
							regulator-always-on;
							regulator-ramp-delay = <0x2ee0>;
							regulator-initial-mode = <0x03>;
							phandle = <0x46>;
						};

						LDO30 {
							regulator-name = "vdd_ldo30";
							regulator-min-microvolt = <0x1b7740>;
							regulator-max-microvolt = <0x1cfde0>;
							regulator-always-on;
							regulator-ramp-delay = <0x2ee0>;
							regulator-initial-mode = <0x03>;
							phandle = <0x47>;
						};
					};
				};
			};

			acpm_mfd_bus@15961000 {
				status = "okay";
				#address-cells = <0x01>;
				#size-cells = <0x00>;

				s2mps26mfd@2f {
					compatible = "samsung,s2mps26mfd";
					acpm-ipc-channel = <0x02>;
					acpm-speedy-channel = <0x01>;
					s2mps26,wakeup = "enabled";
					reg = <0x2f>;
					wtsr_en = <0x01>;
					adc_mode = <0x01>;

					s2mps26-gpio {
						gpio-controller;
						#gpio-cells = <0x02>;
						samsung,npins = <0x1a>;
						status = "okay";
						phandle = <0x16>;
					};

					regulators {

						BUCK1 {
							regulator-name = "vdd_mif";
							regulator-min-microvolt = <0x61a80>;
							regulator-max-microvolt = <0x13d620>;
							regulator-ramp-delay = <0x1770>;
							regulator-initial-mode = <0x01>;
							regulator-always-on;
							phandle = <0x48>;
						};

						BUCK2 {
							regulator-name = "vdd_sram";
							regulator-min-microvolt = <0x61a80>;
							regulator-max-microvolt = <0x13d620>;
							regulator-ramp-delay = <0x1770>;
							regulator-initial-mode = <0x01>;
							regulator-always-on;
							phandle = <0x49>;
						};

						BUCK3 {
							regulator-name = "vdd_cam_ph1";
							regulator-min-microvolt = <0x61a80>;
							regulator-max-microvolt = <0x13d620>;
							regulator-ramp-delay = <0x1770>;
							regulator-initial-mode = <0x01>;
							regulator-always-on;
							phandle = <0x4a>;
						};

						BUCK4 {
							regulator-name = "vdd_cam_ph2";
							regulator-min-microvolt = <0x61a80>;
							regulator-max-microvolt = <0x13d620>;
							regulator-ramp-delay = <0x1770>;
							regulator-initial-mode = <0x01>;
							regulator-always-on;
							phandle = <0x4b>;
						};

						BUCK5 {
							regulator-name = "vdd_npu_ph1";
							regulator-min-microvolt = <0x61a80>;
							regulator-max-microvolt = <0x13d620>;
							regulator-ramp-delay = <0x1770>;
							regulator-initial-mode = <0x01>;
							regulator-always-on;
							phandle = <0x4c>;
						};

						BUCK6 {
							regulator-name = "vdd_npu_ph2";
							regulator-min-microvolt = <0x61a80>;
							regulator-max-microvolt = <0x13d620>;
							regulator-ramp-delay = <0x1770>;
							regulator-initial-mode = <0x01>;
							regulator-always-on;
							phandle = <0x4d>;
						};

						BUCK7 {
							regulator-name = "vdd_npu_ph3";
							regulator-min-microvolt = <0x61a80>;
							regulator-max-microvolt = <0x13d620>;
							regulator-ramp-delay = <0x1770>;
							regulator-initial-mode = <0x01>;
							regulator-always-on;
							phandle = <0x4e>;
						};

						BUCK_SR1 {
							regulator-name = "vdd_lldo";
							regulator-min-microvolt = <0x927c0>;
							regulator-max-microvolt = <0x149970>;
							regulator-always-on;
							regulator-ramp-delay = <0x1770>;
							regulator-initial-mode = <0x03>;
							phandle = <0x4f>;
						};

						BUCKB {
							regulator-name = "vdd_hldo";
							regulator-min-microvolt = <0x2dc6c0>;
							regulator-max-microvolt = <0x36ee80>;
							regulator-always-on;
							regulator-ramp-delay = <0x1770>;
							regulator-initial-mode = <0x03>;
							phandle = <0x50>;
						};

						LDO1 {
							regulator-name = "vdd_ldo1s";
							regulator-min-microvolt = <0x61a80>;
							regulator-max-microvolt = <0x13d620>;
							regulator-ramp-delay = <0x2ee0>;
							regulator-initial-mode = <0x01>;
							regulator-always-on;
							phandle = <0x51>;
						};

						LDO3 {
							regulator-name = "vdd_ldo3s";
							regulator-min-microvolt = <0x61a80>;
							regulator-max-microvolt = <0x13d620>;
							regulator-ramp-delay = <0x2ee0>;
							regulator-initial-mode = <0x01>;
							regulator-always-on;
							phandle = <0x52>;
						};

						LDO4 {
							regulator-name = "vdd_ldo4s";
							regulator-min-microvolt = <0x61a80>;
							regulator-max-microvolt = <0x13d620>;
							regulator-always-on;
							regulator-ramp-delay = <0x2ee0>;
							regulator-initial-mode = <0x03>;
							phandle = <0x53>;
						};

						LDO6 {
							regulator-name = "vdd_ldo6s";
							regulator-min-microvolt = <0x61a80>;
							regulator-max-microvolt = <0x13d620>;
							regulator-always-on;
							regulator-ramp-delay = <0x2ee0>;
							regulator-initial-mode = <0x03>;
							phandle = <0x54>;
						};

						LDO7 {
							regulator-name = "AVDD_CSI_0P85";
							regulator-min-microvolt = <0x61a80>;
							regulator-max-microvolt = <0x13d620>;
							regulator-ramp-delay = <0x2ee0>;
							regulator-initial-mode = <0x01>;
							regulator-always-on;
							phandle = <0x55>;
						};

						LDO8 {
							regulator-name = "vdd_ldo8s";
							regulator-min-microvolt = <0x61a80>;
							regulator-max-microvolt = <0x13d620>;
							regulator-ramp-delay = <0x2ee0>;
							regulator-initial-mode = <0x01>;
							regulator-always-on;
							phandle = <0x56>;
						};

						LDO9 {
							regulator-name = "vdd_ldo9s";
							regulator-min-microvolt = <0x61a80>;
							regulator-max-microvolt = <0x13d620>;
							regulator-ramp-delay = <0x2ee0>;
							regulator-initial-mode = <0x01>;
							regulator-always-on;
							phandle = <0x57>;
						};

						LDO14 {
							regulator-name = "vdd_ldo14s";
							regulator-min-microvolt = <0x1b7740>;
							regulator-max-microvolt = <0x337f98>;
							regulator-always-on;
							regulator-ramp-delay = <0x2ee0>;
							regulator-initial-mode = <0x03>;
							phandle = <0x58>;
						};

						LDO15 {
							regulator-name = "vdd_ldo15s";
							regulator-min-microvolt = <0x1b7740>;
							regulator-max-microvolt = <0x337f98>;
							regulator-always-on;
							regulator-ramp-delay = <0x2ee0>;
							regulator-initial-mode = <0x03>;
							phandle = <0x59>;
						};

						LDO16 {
							regulator-name = "vdd33_usb";
							regulator-min-microvolt = <0x1b7740>;
							regulator-max-microvolt = <0x337f98>;
							regulator-ramp-delay = <0x2ee0>;
							regulator-initial-mode = <0x03>;
							phandle = <0x13>;
						};

						LDO17 {
							regulator-name = "vdd_ldo17s";
							regulator-min-microvolt = <0x1b7740>;
							regulator-max-microvolt = <0x337f98>;
							regulator-always-on;
							regulator-ramp-delay = <0x2ee0>;
							regulator-initial-mode = <0x03>;
							phandle = <0x1c>;
						};

						LDO18 {
							regulator-name = "vdd_ldo18s";
							regulator-min-microvolt = <0x1b7740>;
							regulator-max-microvolt = <0x337f98>;
							regulator-always-on;
							regulator-ramp-delay = <0x2ee0>;
							regulator-initial-mode = <0x03>;
							phandle = <0x5a>;
						};

						LDO19 {
							regulator-name = "vdd_ldo19s";
							regulator-min-microvolt = <0x1b7740>;
							regulator-max-microvolt = <0x337f98>;
							regulator-always-on;
							regulator-ramp-delay = <0x2ee0>;
							regulator-initial-mode = <0x03>;
							phandle = <0x5b>;
						};

						LDO20 {
							regulator-name = "vdd_ldo20s";
							regulator-min-microvolt = <0x1b7740>;
							regulator-max-microvolt = <0x337f98>;
							regulator-always-on;
							regulator-ramp-delay = <0x2ee0>;
							regulator-initial-mode = <0x03>;
							phandle = <0x5c>;
						};
					};
				};
			};

			acpm_mfd_bus@15962000 {
				status = "okay";
				#address-cells = <0x01>;
				#size-cells = <0x00>;

				s2mpm07mfd@3f {
					compatible = "samsung,s2mpm07mfd";
					acpm-ipc-channel = <0x02>;
					s2mpm07,wakeup = "enabled";
					reg = <0x3f>;

					s2mpm07-gpio {
						gpio-controller;
						#gpio-cells = <0x02>;
						samsung,npins = <0x08>;
						status = "okay";
						phandle = <0x5d>;
					};

					regulators {

						BUCK1 {
							regulator-name = "buck1r";
							regulator-min-microvolt = <0x61a80>;
							regulator-max-microvolt = <0x13d620>;
							regulator-ramp-delay = <0x1770>;
							regulator-initial-mode = <0x03>;
							regulator-always-on;
							phandle = <0x5e>;
						};

						LDO11 {
							regulator-name = "vdd_ldo11r";
							regulator-min-microvolt = <0x186a00>;
							regulator-max-microvolt = <0x337f98>;
							regulator-ramp-delay = <0x2ee0>;
							regulator-initial-mode = <0x03>;
							regulator-always-on;
							phandle = <0x5f>;
						};

						LDO18 {
							regulator-name = "vdd_ldo18r";
							regulator-min-microvolt = <0x186a00>;
							regulator-max-microvolt = <0x337f98>;
							regulator-ramp-delay = <0x2ee0>;
							regulator-initial-mode = <0x03>;
							regulator-always-on;
							phandle = <0x60>;
						};

						LDO19 {
							regulator-name = "vdd_ldo19r";
							regulator-min-microvolt = <0x186a00>;
							regulator-max-microvolt = <0x337f98>;
							regulator-ramp-delay = <0x2ee0>;
							regulator-initial-mode = <0x03>;
							regulator-always-on;
							phandle = <0x61>;
						};
					};
				};
			};

			hs_tune {
				status = "disabled";
				repeater_tune_cnt = <0x05>;
				phandle = <0x14>;

				repeater_tune1 {
					tune_name = "eusb_mode_control";
					tune_value = <0x50 0x0a>;
				};

				repeater_tune2 {
					tune_name = "usb2_tx_adjust_port1";
					tune_value = <0x70 0x7d>;
				};

				repeater_tune3 {
					tune_name = "usb2_hs_rx_pre_emphasus_p1";
					tune_value = <0x71 0x3e>;
				};

				repeater_tune4 {
					tune_name = "usb2_disconnect_squelch_port1";
					tune_value = <0x73 0x86>;
				};

				repeater_tune5 {
					tune_name = "eusb_rx_adjust_port1";
					tune_value = <0x79 0x70>;
				};
			};

			ss_tune {
				status = "disabled";
				ss_tune_cnt = <0x0d>;
				phandle = <0x15>;

				ss_tune1 {
					tune_name = "tx_eq_pre_g1";
					tune_value = <0xffffffff 0xffffffff>;
				};

				ss_tune2 {
					tune_name = "tx_eq_pre_g2";
					tune_value = <0xffffffff 0xffffffff>;
				};

				ss_tune3 {
					tune_name = "tx_eq_post_g1";
					tune_value = <0xffffffff 0xffffffff>;
				};

				ss_tune4 {
					tune_name = "tx_eq_post_g2";
					tune_value = <0xffffffff 0xffffffff>;
				};

				ss_tune5 {
					tune_name = "tx_eq_main_g1";
					tune_value = <0xffffffff 0xffffffff>;
				};

				ss_tune6 {
					tune_name = "tx_eq_main_g2";
					tune_value = <0xffffffff 0xffffffff>;
				};

				ss_tune7 {
					tune_name = "tx_vswing_lvl";
					tune_value = <0xffffffff 0xffffffff>;
				};

				ss_tune8 {
					tune_name = "rx_eq_att_lvl";
					tune_value = <0xffffffff 0xffffffff>;
				};

				ss_tune9 {
					tune_name = "rx_eq_afe_gain";
					tune_value = <0xffffffff 0xffffffff>;
				};

				ss_tune10 {
					tune_name = "rx_eq_ctle_boost";
					tune_value = <0xffffffff 0xffffffff>;
				};

				ss_tune11 {
					tune_name = "rx_term_ctrl";
					tune_value = <0xffffffff 0xffffffff>;
				};

				ss_tune12 {
					tune_name = "tx_term_ctrl";
					tune_value = <0xffffffff 0xffffffff>;
				};

				ss_tune13 {
					tune_name = "tx_rxdet_time";
					tune_value = <0xffffffff 0xffffffff>;
				};
			};

			usb_notifier {
				compatible = "samsung,usb-notifier";
				udc = <0xffffffff>;
				status = "okay";
			};

			vbat {
				compatible = "regulator-fixed";
				regulator-name = "VBAT";
				regulator-min-microvolt = <0x401640>;
				regulator-max-microvolt = <0x401640>;
				regulator-boot-on;
				phandle = <0x0d>;
			};

			audio-codec-dummy {
				compatible = "snd-soc-dummy";
				#sound-dai-cells = <0x00>;
				phandle = <0x62>;
			};

			audio-cpu-dummy {
				compatible = "samsung,dummy-cpu";
				#sound-dai-cells = <0x00>;
				phandle = <0x63>;
			};

			sound {
				compatible = "samsung,exynos-sound";
				clock-names = "xclkout";
				clocks = <0xffffffff 0xa8c>;
				MICBIAS1-supply = <0x08>;
				MICBIAS2-supply = <0x08>;
				MICBIAS3-supply = <0x08>;
				dmas = <0xffffffff 0xffffffff>;
				samsung,routing = "DMIC1\0MICBIAS1\0DMIC2\0MICBIAS2\0DMIC3\0MICBIAS3\0RECEIVER\0Left SPK\0SPEAKER\0Right SPK\0VOUTPUT\0ABOX UAIF0 Playback\0ABOX UAIF0 Capture\0VINPUT1\0BLUETOOTH SPK\0ABOX UAIF2 Playback\0ABOX UAIF2 Capture\0BLUETOOTH MIC\0USB SPK\0ABOX USB Playback\0ABOX USB Capture\0USB MIC\0FWD SPK\0ABOX FWD Playback\0ABOX FWD Capture\0FWD MIC\0VTS Virtual Output\0VTS Virtual Output Mux\0PAD DPDM\0DMIC1\0PAD DPDM\0DMIC2\0PAD DPDM\0DMIC3\0PAD DPDM\0DMIC4";
				samsung,codec = <0x09 0x0a>;
				samsung,prefix = "Left\0Right";
				samsung,aux = <0xffffffff 0xffffffff>;

				rdma0 {

					cpu {
						sound-dai = <0xffffffff 0x00>;
					};

					platform {
						sound-dai = <0xffffffff 0x00>;
					};
				};

				rdma1 {

					cpu {
						sound-dai = <0xffffffff 0x00>;
					};

					platform {
						sound-dai = <0xffffffff 0x00>;
					};
				};

				rdma2 {

					cpu {
						sound-dai = <0xffffffff 0x00>;
					};

					platform {
						sound-dai = <0xffffffff 0x00>;
					};
				};

				rdma3 {

					cpu {
						sound-dai = <0xffffffff 0x00>;
					};

					platform {
						sound-dai = <0xffffffff 0x00>;
					};
				};

				rdma4 {

					cpu {
						sound-dai = <0xffffffff 0x00>;
					};

					platform {
						sound-dai = <0xffffffff 0x00>;
					};
				};

				rdma5 {

					cpu {
						sound-dai = <0xffffffff 0x00>;
					};

					platform {
						sound-dai = <0xffffffff 0x00>;
					};
				};

				rdma6 {

					cpu {
						sound-dai = <0xffffffff 0x00>;
					};

					platform {
						sound-dai = <0xffffffff 0x00>;
					};
				};

				rdma7 {

					cpu {
						sound-dai = <0xffffffff 0x00>;
					};

					platform {
						sound-dai = <0xffffffff 0x00>;
					};
				};

				rdma8 {

					cpu {
						sound-dai = <0xffffffff 0x00>;
					};

					platform {
						sound-dai = <0xffffffff 0x00>;
					};
				};

				rdma9 {

					cpu {
						sound-dai = <0xffffffff 0x00>;
					};

					platform {
						sound-dai = <0xffffffff 0x00>;
					};
				};

				rdma10 {

					cpu {
						sound-dai = <0xffffffff 0x00>;
					};

					platform {
						sound-dai = <0xffffffff 0x00>;
					};
				};

				rdma11 {

					cpu {
						sound-dai = <0xffffffff 0x00>;
					};

					platform {
						sound-dai = <0xffffffff 0x00>;
					};
				};

				wdma0 {

					cpu {
						sound-dai = <0xffffffff 0x00>;
					};

					platform {
						sound-dai = <0xffffffff 0x00>;
					};
				};

				wdma1 {

					cpu {
						sound-dai = <0xffffffff 0x00>;
					};

					platform {
						sound-dai = <0xffffffff 0x00>;
					};
				};

				wdma2 {

					cpu {
						sound-dai = <0xffffffff 0x00>;
					};

					platform {
						sound-dai = <0xffffffff 0x00>;
					};
				};

				wdma3 {

					cpu {
						sound-dai = <0xffffffff 0x00>;
					};

					platform {
						sound-dai = <0xffffffff 0x00>;
					};
				};

				wdma4 {

					cpu {
						sound-dai = <0xffffffff 0x00>;
					};

					platform {
						sound-dai = <0xffffffff 0x00>;
					};
				};

				wdma5 {

					cpu {
						sound-dai = <0xffffffff 0x00>;
					};

					platform {
						sound-dai = <0xffffffff 0x00>;
					};
				};

				wdma6 {

					cpu {
						sound-dai = <0xffffffff 0x00>;
					};

					platform {
						sound-dai = <0xffffffff 0x00>;
					};
				};

				wdma7 {

					cpu {
						sound-dai = <0xffffffff 0x00>;
					};

					platform {
						sound-dai = <0xffffffff 0x00>;
					};
				};

				wdma8 {

					cpu {
						sound-dai = <0xffffffff 0x00>;
					};

					platform {
						sound-dai = <0xffffffff 0x00>;
					};
				};

				wdma9 {

					cpu {
						sound-dai = <0xffffffff 0x00>;
					};

					platform {
						sound-dai = <0xffffffff 0x00>;
					};
				};

				wdma10 {

					cpu {
						sound-dai = <0xffffffff 0x00>;
					};

					platform {
						sound-dai = <0xffffffff 0x00>;
					};
				};

				wdma11 {

					cpu {
						sound-dai = <0xffffffff 0x00>;
					};

					platform {
						sound-dai = <0xffffffff 0x00>;
					};
				};

				vts0 {

					cpu {
						sound-dai = <0xffffffff 0x00>;
					};

					platform {
						sound-dai = <0xffffffff>;
					};
				};

				vts1 {

					cpu {
						sound-dai = <0xffffffff 0x01>;
					};

					platform {
						sound-dai = <0xffffffff>;
					};
				};

				dp0_audio {

					cpu {
						sound-dai = <0xffffffff 0x00>;
					};

					platform {
						sound-dai = <0xffffffff>;
					};
				};

				dp1_audio {

					cpu {
						sound-dai = <0xffffffff 0x01>;
					};

					platform {
						sound-dai = <0xffffffff>;
					};
				};

				dual0 {

					cpu {
						sound-dai = <0xffffffff>;
					};

					platform {
						sound-dai = <0xffffffff>;
					};
				};

				dual1 {

					cpu {
						sound-dai = <0xffffffff>;
					};

					platform {
						sound-dai = <0xffffffff>;
					};
				};

				dual2 {

					cpu {
						sound-dai = <0xffffffff>;
					};

					platform {
						sound-dai = <0xffffffff>;
					};
				};

				dual3 {

					cpu {
						sound-dai = <0xffffffff>;
					};

					platform {
						sound-dai = <0xffffffff>;
					};
				};

				dual4 {

					cpu {
						sound-dai = <0xffffffff>;
					};

					platform {
						sound-dai = <0xffffffff>;
					};
				};

				dual5 {

					cpu {
						sound-dai = <0xffffffff>;
					};

					platform {
						sound-dai = <0xffffffff>;
					};
				};

				dual6 {

					cpu {
						sound-dai = <0xffffffff>;
					};

					platform {
						sound-dai = <0xffffffff>;
					};
				};

				dual7 {

					cpu {
						sound-dai = <0xffffffff>;
					};

					platform {
						sound-dai = <0xffffffff>;
					};
				};

				dual8 {

					cpu {
						sound-dai = <0xffffffff>;
					};

					platform {
						sound-dai = <0xffffffff>;
					};
				};

				dual9 {

					cpu {
						sound-dai = <0xffffffff>;
					};

					platform {
						sound-dai = <0xffffffff>;
					};
				};

				dual10 {

					cpu {
						sound-dai = <0xffffffff>;
					};

					platform {
						sound-dai = <0xffffffff>;
					};
				};

				dual11 {

					cpu {
						sound-dai = <0xffffffff>;
					};

					platform {
						sound-dai = <0xffffffff>;
					};
				};

				ddma0 {

					cpu {
						sound-dai = <0xffffffff>;
					};

					platform {
						sound-dai = <0xffffffff>;
					};
				};

				ddma1 {

					cpu {
						sound-dai = <0xffffffff>;
					};

					platform {
						sound-dai = <0xffffffff>;
					};
				};

				ddma2 {

					cpu {
						sound-dai = <0xffffffff>;
					};

					platform {
						sound-dai = <0xffffffff>;
					};
				};

				ddma3 {

					cpu {
						sound-dai = <0xffffffff>;
					};

					platform {
						sound-dai = <0xffffffff>;
					};
				};

				ddma4 {

					cpu {
						sound-dai = <0xffffffff>;
					};

					platform {
						sound-dai = <0xffffffff>;
					};
				};

				ddma5 {

					cpu {
						sound-dai = <0xffffffff>;
					};

					platform {
						sound-dai = <0xffffffff>;
					};
				};

				uaif0 {
					format = "dsp_a";

					cpu {
						sound-dai = <0xffffffff>;
					};
				};

				uaif1 {
					format = "dsp_a";

					cpu {
						sound-dai = <0xffffffff>;
					};

					codec {
						sound-dai = <0x09 0x00 0x0a 0x00>;
					};
				};

				uaif2 {
					format = "i2s";

					cpu {
						sound-dai = <0xffffffff>;
					};
				};

				uaif3 {
					format = "dsp_a";

					cpu {
						sound-dai = <0xffffffff>;
					};
				};

				uaif4 {
					format = "dsp_a";

					cpu {
						sound-dai = <0xffffffff>;
					};
				};

				uaif5 {
					format = "dsp_a";

					cpu {
						sound-dai = <0xffffffff>;
					};
				};

				uaif6 {
					format = "dsp_a";
					bitclock-master;
					bitclock-inversion;
					frame-master;

					cpu {
						sound-dai = <0xffffffff>;
					};

					codec {
						sound-dai = <0xffffffff 0x00>;
					};
				};

				dsif0 {
					format = "pdm";

					cpu {
						sound-dai = <0xffffffff>;
					};
				};

				udma_rd0 {

					cpu {
						sound-dai = <0xffffffff>;
					};
				};

				udma_rd1 {

					cpu {
						sound-dai = <0xffffffff>;
					};
				};

				udma_wr0 {

					cpu {
						sound-dai = <0xffffffff>;
					};
				};

				udma_wr1 {

					cpu {
						sound-dai = <0xffffffff>;
					};
				};

				udma_wr_dual0 {

					cpu {
						sound-dai = <0xffffffff>;
					};
				};

				udma_wr_dual1 {

					cpu {
						sound-dai = <0xffffffff>;
					};
				};

				udma_wr_dbg0 {

					cpu {
						sound-dai = <0xffffffff>;
					};
				};

				rdma0_be {

					cpu {
						sound-dai = <0xffffffff 0x01>;
					};

					platform {
						sound-dai = <0xffffffff 0x01>;
					};
				};

				rdma1_be {

					cpu {
						sound-dai = <0xffffffff 0x01>;
					};

					platform {
						sound-dai = <0xffffffff 0x01>;
					};
				};

				rdma2_be {

					cpu {
						sound-dai = <0xffffffff 0x01>;
					};

					platform {
						sound-dai = <0xffffffff 0x01>;
					};
				};

				rdma3_be {

					cpu {
						sound-dai = <0xffffffff 0x01>;
					};

					platform {
						sound-dai = <0xffffffff 0x01>;
					};
				};

				rdma4_be {

					cpu {
						sound-dai = <0xffffffff 0x01>;
					};

					platform {
						sound-dai = <0xffffffff 0x01>;
					};
				};

				rdma5_be {

					cpu {
						sound-dai = <0xffffffff 0x01>;
					};

					platform {
						sound-dai = <0xffffffff 0x01>;
					};
				};

				rdma6_be {

					cpu {
						sound-dai = <0xffffffff 0x01>;
					};

					platform {
						sound-dai = <0xffffffff 0x01>;
					};
				};

				rdma7_be {

					cpu {
						sound-dai = <0xffffffff 0x01>;
					};

					platform {
						sound-dai = <0xffffffff 0x01>;
					};
				};

				rdma8_be {

					cpu {
						sound-dai = <0xffffffff 0x01>;
					};

					platform {
						sound-dai = <0xffffffff 0x01>;
					};
				};

				rdma9_be {

					cpu {
						sound-dai = <0xffffffff 0x01>;
					};

					platform {
						sound-dai = <0xffffffff 0x01>;
					};
				};

				rdma10_be {

					cpu {
						sound-dai = <0xffffffff 0x01>;
					};

					platform {
						sound-dai = <0xffffffff 0x01>;
					};
				};

				rdma11_be {

					cpu {
						sound-dai = <0xffffffff 0x01>;
					};

					platform {
						sound-dai = <0xffffffff 0x01>;
					};
				};

				wdma0_be {

					cpu {
						sound-dai = <0xffffffff 0x01>;
					};

					platform {
						sound-dai = <0xffffffff 0x01>;
					};
				};

				wdma1_be {

					cpu {
						sound-dai = <0xffffffff 0x01>;
					};

					platform {
						sound-dai = <0xffffffff 0x01>;
					};
				};

				wdma2_be {

					cpu {
						sound-dai = <0xffffffff 0x01>;
					};

					platform {
						sound-dai = <0xffffffff 0x01>;
					};
				};

				wdma3_be {

					cpu {
						sound-dai = <0xffffffff 0x01>;
					};

					platform {
						sound-dai = <0xffffffff 0x01>;
					};
				};

				wdma4_be {

					cpu {
						sound-dai = <0xffffffff 0x01>;
					};

					platform {
						sound-dai = <0xffffffff 0x01>;
					};
				};

				wdma5_be {

					cpu {
						sound-dai = <0xffffffff 0x01>;
					};

					platform {
						sound-dai = <0xffffffff 0x01>;
					};
				};

				wdma6_be {

					cpu {
						sound-dai = <0xffffffff 0x01>;
					};

					platform {
						sound-dai = <0xffffffff 0x01>;
					};
				};

				wdma7_be {

					cpu {
						sound-dai = <0xffffffff 0x01>;
					};

					platform {
						sound-dai = <0xffffffff 0x01>;
					};
				};

				wdma8_be {

					cpu {
						sound-dai = <0xffffffff 0x01>;
					};

					platform {
						sound-dai = <0xffffffff 0x01>;
					};
				};

				wdma9_be {

					cpu {
						sound-dai = <0xffffffff 0x01>;
					};

					platform {
						sound-dai = <0xffffffff 0x01>;
					};
				};

				wdma10_be {

					cpu {
						sound-dai = <0xffffffff 0x01>;
					};

					platform {
						sound-dai = <0xffffffff 0x01>;
					};
				};

				wdma11_be {

					cpu {
						sound-dai = <0xffffffff 0x01>;
					};

					platform {
						sound-dai = <0xffffffff 0x01>;
					};
				};

				usb {

					cpu {
						sound-dai = <0xffffffff 0x00>;
					};
				};

				fwd {

					cpu {
						sound-dai = <0xffffffff 0x01>;
					};
				};
			};
		};
	};

	fragment@9 {
		target = <0xffffffff>;

		__overlay__ {
			status = "okay";
		};
	};

	fragment@10 {
		target = <0xffffffff>;

		__overlay__ {

			key-volup {
				samsung,pins = "gpa3-0";
				samsung,pin-function = <0x0f>;
				samsung,pin-pud = <0x03>;
				samsung,pin-drv = <0x03>;
				phandle = <0x05>;
			};

			tsp_int_active {
				samsung,pins = "gpa1-2";
				samsung,pin-function = <0x0f>;
				samsung,pin-pud = <0x03>;
				samsung,pin-drv = <0x03>;
				phandle = <0x19>;
			};

			tsp_int_sleep {
				samsung,pins = "gpa1-2";
				samsung,pin-function = <0x00>;
				samsung,pin-pud = <0x01>;
				phandle = <0x1a>;
			};

			eusb_ctrl_sel {
				samsung,pins = "gpa4-1";
				samsung,pin-function = <0x01>;
				samsung,pin-pud = <0x00>;
				phandle = <0x64>;
			};
		};
	};

	fragment@11 {
		target = <0xffffffff>;

		__overlay__ {

			pm-wrstbi {
				samsung,pins = "gpm21-0";
				samsung,pin-con-pdn = <0x03>;
				samsung,pin-pud-pdn = <0x00>;
				phandle = <0x06>;
			};
		};
	};

	fragment@12 {
		target = <0xffffffff>;

		__overlay__ {

			sub-pmic-irq {
				samsung,pins = "gpp7-2";
				samsung,pin-function = <0x00>;
				samsung,pin-pud = <0x00>;
				samsung,pin-drv = <0x00>;
				phandle = <0x0f>;
			};
		};
	};

	fragment@13 {
		target = <0xffffffff>;

		__overlay__ {

			smpl-warn {
				samsung,pins = "gpg0-4";
				samsung,pin-function = <0x0f>;
				samsung,pin-pud = <0x00>;
				samsung,pin-drv = <0x00>;
				phandle = <0x07>;
			};
		};
	};

	fragment@14 {
		target = <0xffffffff>;

		__overlay__ {

			ext-bin@0 {
				compatible = "samsung,abox-ext-bin";
				samsung,name = "dax_param.bin";
				samsung,area = <0x01>;
				samsung,offset = <0x510000>;
				samsung,changeable;
				phandle = <0x65>;
			};

			ext-bin@1 {
				compatible = "samsung,abox-ext-bin";
				samsung,name = "AP_AUDIO_SLSI.bin";
				samsung,area = <0x01>;
				samsung,offset = <0x52e000>;
				samsung,changeable;
				phandle = <0x66>;
			};

			ext-bin@2 {
				compatible = "samsung,abox-ext-bin";
				samsung,name = "APBargeIn_AUDIO_SLSI.bin";
				samsung,area = <0x01>;
				samsung,offset = <0x5da800>;
				samsung,changeable;
				phandle = <0x67>;
			};

			ext-bin@3 {
				compatible = "samsung,abox-ext-bin";
				samsung,name = "APBiBF_AUDIO_SLSI.bin";
				samsung,area = <0x01>;
				samsung,offset = <0x5dd800>;
				samsung,changeable;
				phandle = <0x68>;
			};

			ext-bin@4 {
				compatible = "samsung,abox-ext-bin";
				samsung,name = "APDV_AUDIO_SLSI.bin";
				samsung,area = <0x01>;
				samsung,offset = <0x5de800>;
				samsung,changeable;
				phandle = <0x69>;
			};

			ext-bin@5 {
				compatible = "samsung,abox-ext-bin";
				samsung,name = "SoundBoosterParam.bin";
				samsung,area = <0x01>;
				samsung,offset = <0x65e800>;
				samsung,changeable;
				phandle = <0x6a>;
			};

			ext-bin@6 {
				compatible = "samsung,abox-ext-bin";
				samsung,name = "atune.bin";
				samsung,area = <0x01>;
				samsung,offset = "\0f(";
				samsung,changeable;
				phandle = <0x6b>;
			};

			ext-bin@7 {
				compatible = "samsung,abox-ext-bin";
				samsung,name = "rxse.bin";
				samsung,area = <0x01>;
				samsung,offset = "\0lP";
				phandle = <0x6c>;
			};

			ext-bin@8 {
				compatible = "samsung,abox-ext-bin";
				samsung,name = "avsyncmix.bin";
				samsung,area = <0x01>;
				samsung,offset = "\0{x";
				phandle = <0x6d>;
			};

			ext-bin@9 {
				compatible = "samsung,abox-ext-bin";
				samsung,name = "txse1.bin";
				samsung,area = <0x01>;
				samsung,offset = <0x1800000>;
				phandle = <0x6e>;
			};

			ext-bin@10 {
				compatible = "samsung,abox-ext-bin";
				samsung,name = "txse2.bin";
				samsung,area = <0x01>;
				samsung,offset = <0x1e00000>;
				phandle = <0x6f>;
			};

			ext-bin@11 {
				compatible = "samsung,abox-ext-bin";
				samsung,name = "bidirmic.bin";
				samsung,area = <0x01>;
				samsung,offset = <0x1e72800>;
				phandle = <0x70>;
			};

			ext-bin@12 {
				compatible = "samsung,abox-ext-bin";
				samsung,name = "volumemonitor.bin";
				samsung,area = <0x01>;
				samsung,offset = <0x1f27800>;
				phandle = <0x71>;
			};

			ext-bin@13 {
				compatible = "samsung,abox-ext-bin";
				samsung,name = "sb_others.bin";
				samsung,area = <0x01>;
				samsung,offset = <0x1f40800>;
				phandle = <0x72>;
			};

			ext-bin@14 {
				compatible = "samsung,abox-ext-bin";
				samsung,name = "listenbackeffect.bin";
				samsung,area = <0x01>;
				samsung,offset = <0x206c800>;
				phandle = <0x73>;
			};

			ext-bin@15 {
				compatible = "samsung,abox-ext-bin";
				samsung,name = "a2dpcom.bin";
				samsung,area = <0x01>;
				samsung,offset = <0x20d0800>;
				phandle = <0x74>;
			};

			ext-bin@16 {
				compatible = "samsung,abox-ext-bin";
				samsung,name = "dolby.bin";
				samsung,area = <0x01>;
				samsung,offset = <0x2c0000>;
				phandle = <0x75>;
			};

			ext-bin@17 {
				compatible = "samsung,abox-ext-bin";
				samsung,name = "sb_music.bin";
				samsung,area = <0x01>;
				samsung,offset = <0x2250800>;
				phandle = <0x76>;
			};
		};
	};

	fragment@15 {
		target = <0xffffffff>;

		__overlay__ {
			pinctrl-names;
		};
	};

	fragment@16 {
		target = <0xffffffff>;

		__overlay__ {

			cs35l41-r-reset {
				samsung,pins = "gpb3-0";
				samsung,pin-con-pdn = <0x03>;
				samsung,pin-pud-pdn = <0x00>;
				phandle = <0x0b>;
			};

			cs35l41-l-reset {
				samsung,pins = "gpb3-3";
				samsung,pin-con-pdn = <0x03>;
				samsung,pin-pud-pdn = <0x00>;
				phandle = <0x0e>;
			};
		};
	};

	fragment@17 {
		target = <0xffffffff>;

		__overlay__ {
			#address-cells = <0x01>;
			#size-cells = <0x00>;
			status = "okay";
			clock-frequency = <0x61a80>;

			cs35l41@40 {
				#sound-dai-cells = <0x01>;
				compatible = "cirrus,cs35l41";
				reg = <0x40>;
				interrupt-parent = <0xffffffff>;
				interrupts = <0x04 0x00 0x00>;
				pinctrl-names = "default";
				pinctrl-0 = <0x0b>;
				reset-gpios = <0xffffffff 0x00 0x00>;
				VA-supply = <0x0c>;
				VP-supply = <0x0d>;
				cirrus,boost-peak-milliamp = <0x1194>;
				cirrus,boost-ind-nanohenry = <0x3e8>;
				cirrus,boost-cap-microfarad = <0x0f>;
				cirrus,dsp-noise-gate-enable;
				cirrus,dsp-noise-gate-delay = <0x02>;
				cirrus,dsp-noise-gate-threshold = <0x06>;
				cirrus,hw-noise-gate-select = <0x3f>;
				cirrus,hw-noise-gate-delay = <0x00>;
				cirrus,hw-noise-gate-threshold = <0x06>;
				cirrus,use-fsync-errata;
				cirrus,asp-sdout-hiz = <0x03>;
				cirrus,right-channel-amp;
				cirrus,mfd-suffix = "_r";
				phandle = <0x0a>;

				cirrus,gpio-config2 {
					cirrus,gpio-src-select = <0x04>;
					cirrus,gpio-output-enable;
				};
			};

			cs35l41@41 {
				#sound-dai-cells = <0x01>;
				compatible = "cirrus,cs35l41";
				reg = <0x41>;
				interrupt-parent = <0xffffffff>;
				interrupts = <0x04 0x00 0x00>;
				pinctrl-names = "default";
				pinctrl-0 = <0x0e>;
				reset-gpios = <0xffffffff 0x03 0x00>;
				VA-supply = <0x0c>;
				VP-supply = <0x0d>;
				cirrus,boost-peak-milliamp = <0x1194>;
				cirrus,boost-ind-nanohenry = <0x3e8>;
				cirrus,boost-cap-microfarad = <0x0f>;
				cirrus,dsp-noise-gate-enable;
				cirrus,dsp-noise-gate-delay = <0x02>;
				cirrus,dsp-noise-gate-threshold = <0x06>;
				cirrus,hw-noise-gate-select = <0x3f>;
				cirrus,hw-noise-gate-delay = <0x00>;
				cirrus,hw-noise-gate-threshold = <0x06>;
				cirrus,use-fsync-errata;
				cirrus,asp-sdout-hiz = <0x03>;
				cirrus,mfd-suffix = [00];
				phandle = <0x09>;

				cirrus,gpio-config2 {
					cirrus,gpio-src-select = <0x04>;
					cirrus,gpio-output-enable;
				};
			};
		};
	};

	fragment@18 {
		target = <0xffffffff>;

		__overlay__ {
			#address-cells = <0x03>;
			#size-cells = <0x00>;
			status = "okay";

			s2mpb02_pmic@59 {
				compatible = "s2mpb02,s2mpb02mfd";
				reg = <0x59 0x00 0x10>;
				s2mpb02,wakeup;
				pinctrl-names = "default";
				pinctrl-0 = <0x0f>;

				regulators {

					s2mpb02-buck1 {
						regulator-name = "S2MPB02_BUCK1";
						regulator-min-microvolt = <0x13d620>;
						regulator-max-microvolt = <0x13d620>;
						phandle = <0x77>;
					};

					s2mpb02-buck2 {
						regulator-name = "S2MPB02_BUCK2";
						regulator-min-microvolt = <0x13d620>;
						regulator-max-microvolt = <0x13d620>;
						phandle = <0x78>;
					};

					s2mpb02-bb {
						regulator-name = "S2MPB02_BB";
						regulator-min-microvolt = <0x27ac40>;
						regulator-max-microvolt = "\0=\t";
						regulator-always-on;
						regulator-boot-on;
						phandle = <0x79>;
					};

					s2mpb02-ldo1 {
						regulator-name = "VDDPHY_1.05V_CAM";
						regulator-min-microvolt = <0x100590>;
						regulator-max-microvolt = <0x100590>;
						phandle = <0x7a>;
					};

					s2mpb02-ldo2 {
						regulator-name = "S2MPB02_LDO2";
						regulator-min-microvolt = <0xf4240>;
						regulator-max-microvolt = <0xf4240>;
						phandle = <0x7b>;
					};

					s2mpb02-ldo3 {
						regulator-name = "VDDD_1.05V_SUB";
						regulator-min-microvolt = <0x100590>;
						regulator-max-microvolt = <0x100590>;
						phandle = <0x7c>;
					};

					s2mpb02-ldo4 {
						regulator-name = "VDDD_1.05V_WIDESUB";
						regulator-min-microvolt = <0x10c8e0>;
						regulator-max-microvolt = <0x10c8e0>;
						phandle = <0x7d>;
					};

					s2mpb02-ldo5 {
						regulator-name = "VDDD_1.05V_VT";
						regulator-min-microvolt = <0x100590>;
						regulator-max-microvolt = <0x100590>;
						phandle = <0x7e>;
					};

					s2mpb02-ldo6 {
						regulator-name = "VDDIO_1.8V_SUB";
						regulator-min-microvolt = <0x1b7740>;
						regulator-max-microvolt = <0x1b7740>;
						phandle = <0x7f>;
					};

					s2mpb02-ldo7 {
						regulator-name = "VDDIO_1.8V_CAM";
						regulator-min-microvolt = <0x1b7740>;
						regulator-max-microvolt = <0x1b7740>;
						phandle = <0x80>;
					};

					s2mpb02-ldo8 {
						regulator-name = "VDDA_1.8V_WIDESUB";
						regulator-min-microvolt = <0x1b7740>;
						regulator-max-microvolt = <0x1b7740>;
						phandle = <0x81>;
					};

					s2mpb02-ldo9 {
						regulator-name = "VDDIO_1.8V_VT";
						regulator-min-microvolt = <0x1b7740>;
						regulator-max-microvolt = <0x1b7740>;
						phandle = <0x82>;
					};

					s2mpb02-ldo10 {
						regulator-name = "S2MPB02_LD10";
						regulator-min-microvolt = <0x1b7740>;
						regulator-max-microvolt = <0x1b7740>;
						phandle = <0x83>;
					};

					s2mpb02-ldo11 {
						regulator-name = "VDDAF_2.8V_SUB";
						regulator-min-microvolt = <0x2ab980>;
						regulator-max-microvolt = <0x2ab980>;
						phandle = <0x84>;
					};

					s2mpb02-ldo12 {
						regulator-name = "VDDA_2.8V_WIDESUB";
						regulator-min-microvolt = <0x2ab980>;
						regulator-max-microvolt = <0x2ab980>;
						phandle = <0x85>;
					};

					s2mpb02-ldo13 {
						regulator-name = "VDDAF_COMMON_CAM";
						regulator-min-microvolt = <0x2ab980>;
						regulator-max-microvolt = <0x2ab980>;
						phandle = <0x86>;
					};

					s2mpb02-ldo14 {
						regulator-name = "VDDA_2.8V_CAM";
						regulator-min-microvolt = <0x2ab980>;
						regulator-max-microvolt = <0x2ab980>;
						phandle = <0x87>;
					};

					s2mpb02-ldo15 {
						regulator-name = "VDDA_2.8V_VT";
						regulator-min-microvolt = <0x2ab980>;
						regulator-max-microvolt = <0x2ab980>;
						phandle = <0x88>;
					};

					s2mpb02-ldo16 {
						regulator-name = "VDDAF_2.8V_VT";
						regulator-min-microvolt = <0x2ab980>;
						regulator-max-microvolt = <0x2ab980>;
						phandle = <0x89>;
					};

					s2mpb02-ldo17 {
						regulator-name = "VDDA_2.8V_SUB";
						regulator-min-microvolt = <0x2ab980>;
						regulator-max-microvolt = <0x2ab980>;
						phandle = <0x8a>;
					};

					s2mpb02-ldo18 {
						regulator-name = "VDDD_2.8V_OIS";
						regulator-min-microvolt = <0x2ab980>;
						regulator-max-microvolt = <0x2ab980>;
						phandle = <0x8b>;
					};
				};
			};
		};
	};

	fragment@19 {
		target = <0xffffffff>;

		__overlay__ {
			status = "okay";
		};
	};

	fragment@20 {
		target = <0xffffffff>;

		__overlay__ {
			status = "okay";
			maximum-speed = "super-speed";
			usb_audio_offloading = <0x01>;
			abox = <0xffffffff>;
			xhci_use_uram_for_audio = <0x01>;
			vdd_ldo5-supply = <0x10>;
			vdd_ldo7-supply = <0x11>;
			vdd_ldo20-supply = <0x12>;
			vdd_ldo16s-supply = <0x13>;
		};
	};

	fragment@21 {
		target = <0xffffffff>;

		__overlay__ {
			status = "okay";
			pinctrl-names = "default";
			phy,gpio_phy_port = <0xffffffff 0x01 0x00>;
			hs_tune_param = <0x14>;
			ss_tune_param = <0x15>;
			vdd_ldo5-supply = <0x10>;
			vdd_ldo7-supply = <0x11>;
			vdd_ldo20-supply = <0x12>;
			vdd_ldo16s-supply = <0x13>;
		};
	};

	fragment@22 {
		target = <0xffffffff>;

		__overlay__ {
			#address-cells = <0x01>;
			#size-cells = <0x00>;

			drmpanel {
				compatible = "samsung,command-ctrl";
				reset-gpios = <0xffffffff 0x00 0x00>;
				dsim_mode = <0xffffffff>;
				reg = <0x00>;
				pinctrl-names = "default";
				pinctrl-0 = <0xffffffff>;
				default-panel = "s6e3fac_1080_2340_cmd";
				phandle = <0x8c>;

				samsung_emulation_video_panel {
					samsung,panel-name = "samsung emulation panel";
					phandle = <0x8d>;

					display-timings {

						640x480@60 {
							exynos,mode-type = <0x48>;
							exynos,refresh-rate = <0x3c>;
							exynos,hactive = <0x280>;
							exynos,hfront-porch = <0x14>;
							exynos,hsync-len = <0x14>;
							exynos,hback-porch = <0x14>;
							exynos,vactive = <0x1e0>;
							exynos,vfront-porch = <0x14>;
							exynos,vsync-len = <0x14>;
							exynos,vback-porch = <0x14>;
							exynos,clock-frequency = <0x5898>;
							exynos,mode-flags = <0x00>;
							exynos,bpc = <0x08>;
							exynos,lp-mode = <0x00>;
							exynos,dsc-en = <0x00>;
							exynos,on-cmds = <0x01 0x11 0x00 0x01 0x29 0x00>;
							exynos,off-cmds = <0x01 0x10 0x00 0x01 0x28 0x00>;
						};
					};
				};

				s6e3fac_1080_2340_cmd {
					samsung,panel-name = "samsung s6e3fac 1080x2340 command mode panel";
					samsung,max-brightness = <0x3ff>;
					samsung,default-brightness = <0x1ff>;
					samsung,data-lane-count = <0x04>;
					samsung,doze-supported;
					samsung,reset-sequence = <0x01 0x00 0x01>;
					samsung,reset-udelay = <0x00 0x1388 0x1388 0x2710>;
					samsung,lcd-size-mm = <0x4b 0xa5>;
					phandle = <0x8e>;

					display-timings {

						1080x2340@60 {
							exynos,mode-type = <0x48>;
							exynos,refresh-rate = <0x3c>;
							exynos,hactive = <0x438>;
							exynos,hfront-porch = <0x01>;
							exynos,hsync-len = <0x01>;
							exynos,hback-porch = <0x01>;
							exynos,vactive = <0x924>;
							exynos,vfront-porch = <0x0f>;
							exynos,vsync-len = <0x01>;
							exynos,vback-porch = <0x01>;
							exynos,clock-frequency = <0x25646>;
							exynos,mode-flags = <0x0a>;
							exynos,bpc = <0x08>;
							exynos,lp-mode = <0x00>;
							exynos,dsc-en = <0x01>;
							exynos,dsc-count = <0x02>;
							exynos,dsc-slice-count = <0x02>;
							exynos,dsc-slice-height = <0x75>;
							exynos,pps-cmds = <0x58 0x11 0x00 0x00 0x89 0x30 0x80 0x09 0x24 0x04 0x38 0x00 0x75 0x02 0x1c 0x02 0x1c 0x02 0x00 0x02 0x0e 0x00 0x20 0x0b 0x64 0x00 0x07 0x00 0x0c 0x00 0xd4 0x00 0xdf 0x18 0x00 0x10 0xf0 0x03 0x0c 0x20 0x00 0x06 0x0b 0x0b 0x33 0x0e 0x1c 0x2a 0x38 0x46 0x54 0x62 0x69 0x70 0x77 0x79 0x7b 0x7d 0x7e 0x01 0x02 0x01 0x00 0x09 0x40 0x09 0xbe 0x19 0xfc 0x19 0xfa 0x19 0xf8 0x1a 0x38 0x1a 0x78 0x1a 0xb6 0x2a 0xf6 0x2b 0x34 0x2b 0x74 0x3b 0x74 0x6b 0xf4 0x00>;
							exynos,on-cmds = <0x01 0x11 0x0a 0x03 0xf0 0x5a 0x5a 0x00 0x03 0xfc 0x5a 0x5a 0x00 0x05 0x2a 0x00 0x00 0x04 0x37 0x00 0x05 0x2b 0x00 0x00 0x09 0x5f 0x00 0x04 0xed 0x04 0x40 0x20 0x00 0x04 0xb0 0x00 0x36 0xc5 0x00 0x02 0xc5 0x01 0x00 0x04 0xb0 0x00 0x3a 0xc5 0x00 0x03 0xc5 0x2d 0x58 0x00 0x04 0xb0 0x00 0x52 0xc5 0x00 0x03 0xc5 0x2d 0x58 0x00 0x02 0x53 0x28 0x00 0x02 0x55 0x01 0x00 0x03 0x51 0x02 0xed 0x00 0x02 0xf7 0x0f 0x00 0x01 0x35 0x00 0x0a 0xb9 0x00 0x00 0x00 0x09 0x00 0x00 0x00 0x11 0x03 0x00 0x03 0xf0 0xa5 0xa5 0x00 0x03 0xfc 0xa5 0xa5 0x00>;
							exynos,vref-cmds = <0x03 0xf0 0x5a 0x5a 0x00 0x03 0x9f 0xa5 0xa5 0x00 0x02 0xf2 0x01 0x00 0x02 0x60 0x18 0x00 0x03 0x9f 0x5a 0x5a 0x00 0x02 0xf7 0x0f 0x00 0x03 0xf0 0xa5 0xa5 0x00>;
							exynos,disp-on-cmds = <0x03 0x9f 0xa5 0xa5 0x00 0x01 0x29 0x00 0x03 0x9f 0x5a 0x5a 0x00>;
							exynos,off-cmds = <0x01 0x10 0x00 0x01 0x28 0x00>;
						};

						1080x2340@120 {
							exynos,mode-type = <0x40>;
							exynos,refresh-rate = <0x78>;
							exynos,hactive = <0x438>;
							exynos,hfront-porch = <0x01>;
							exynos,hsync-len = <0x01>;
							exynos,hback-porch = <0x01>;
							exynos,vactive = <0x924>;
							exynos,vfront-porch = <0x0f>;
							exynos,vsync-len = <0x01>;
							exynos,vback-porch = <0x01>;
							exynos,clock-frequency = <0x4ac8c>;
							exynos,mode-flags = <0x0a>;
							exynos,bpc = <0x08>;
							exynos,lp-mode = <0x00>;
							exynos,dsc-en = <0x01>;
							exynos,dsc-count = <0x02>;
							exynos,dsc-slice-count = <0x02>;
							exynos,dsc-slice-height = <0x75>;
							exynos,pps-cmds = <0x58 0x11 0x00 0x00 0x89 0x30 0x80 0x09 0x24 0x04 0x38 0x00 0x75 0x02 0x1c 0x02 0x1c 0x02 0x00 0x02 0x0e 0x00 0x20 0x0b 0x64 0x00 0x07 0x00 0x0c 0x00 0xd4 0x00 0xdf 0x18 0x00 0x10 0xf0 0x03 0x0c 0x20 0x00 0x06 0x0b 0x0b 0x33 0x0e 0x1c 0x2a 0x38 0x46 0x54 0x62 0x69 0x70 0x77 0x79 0x7b 0x7d 0x7e 0x01 0x02 0x01 0x00 0x09 0x40 0x09 0xbe 0x19 0xfc 0x19 0xfa 0x19 0xf8 0x1a 0x38 0x1a 0x78 0x1a 0xb6 0x2a 0xf6 0x2b 0x34 0x2b 0x74 0x3b 0x74 0x6b 0xf4 0x00>;
							exynos,on-cmds = <0x01 0x11 0x0a 0x03 0xf0 0x5a 0x5a 0x00 0x03 0xfc 0x5a 0x5a 0x00 0x05 0x2a 0x00 0x00 0x04 0x37 0x00 0x05 0x2b 0x00 0x00 0x09 0x5f 0x00 0x04 0xed 0x04 0x40 0x20 0x00 0x04 0xb0 0x00 0x36 0xc5 0x00 0x02 0xc5 0x01 0x00 0x04 0xb0 0x00 0x3a 0xc5 0x00 0x03 0xc5 0x2d 0x58 0x00 0x04 0xb0 0x00 0x52 0xc5 0x00 0x03 0xc5 0x2d 0x58 0x00 0x02 0x53 0x28 0x00 0x02 0x55 0x01 0x00 0x03 0x51 0x02 0xed 0x00 0x02 0xf7 0x0f 0x00 0x01 0x35 0x00 0x0a 0xb9 0x00 0x00 0x00 0x09 0x00 0x00 0x00 0x11 0x03 0x00 0x03 0xf0 0xa5 0xa5 0x00 0x03 0xfc 0xa5 0xa5 0x00>;
							exynos,vref-cmds = <0x03 0xf0 0x5a 0x5a 0x00 0x03 0x9f 0xa5 0xa5 0x00 0x02 0xf2 0x01 0x00 0x02 0x60 0x00 0x00 0x03 0x9f 0x5a 0x5a 0x00 0x02 0xf7 0x0f 0x00 0x03 0xf0 0xa5 0xa5 0x00>;
							exynos,disp-on-cmds = <0x03 0x9f 0xa5 0xa5 0x00 0x01 0x29 0x00 0x03 0x9f 0x5a 0x5a 0x00>;
							exynos,off-cmds = <0x01 0x10 0x00 0x01 0x28 0x00>;
						};

						1080x2340@30 {
							exynos,mode-type = <0x40>;
							exynos,refresh-rate = <0x1e>;
							exynos,hactive = <0x438>;
							exynos,hfront-porch = <0x01>;
							exynos,hsync-len = <0x01>;
							exynos,hback-porch = <0x01>;
							exynos,vactive = <0x924>;
							exynos,vfront-porch = <0x0f>;
							exynos,vsync-len = <0x01>;
							exynos,vback-porch = <0x01>;
							exynos,clock-frequency = <0x12b23>;
							exynos,mode-flags = <0x0a>;
							exynos,bpc = <0x08>;
							exynos,lp-mode = <0x01>;
							exynos,dsc-en = <0x01>;
							exynos,dsc-count = <0x02>;
							exynos,dsc-slice-count = <0x02>;
							exynos,dsc-slice-height = <0x75>;
						};
					};
				};
			};
		};
	};

	fragment@23 {
		target = <0xffffffff>;

		__overlay__ {
			status = "okay";
			dp,aux_sw_oe = <0x16 0x00 0x00>;
			dp,sbu_sw_sel = <0x16 0x01 0x00>;
			dp,usb_con_sel = <0xffffffff 0x01 0x00>;
			pinctrl-names = "default";
		};
	};

	fragment@24 {
		target = <0xffffffff>;

		__overlay__ {
			vcc-supply = <0x17>;
			vccq-supply = <0x18>;
		};
	};

	fragment@25 {
		target = <0xffffffff>;

		__overlay__ {
			#address-cells = <0x01>;
			#size-cells = <0x00>;
			status = "ok";

			touchscreen@0 {
				status = "ok";
				compatible = "stm,stm_ts_spi";
				reg = <0x00>;
				spi-max-frequency = <0x989680>;
				pinctrl-names = "on_state\0off_state";
				pinctrl-0 = <0x19>;
				pinctrl-1 = <0x1a>;
				tsp_io_ldo-supply = <0x1b>;
				tsp_avdd_ldo-supply = <0x1c>;
				sec,irq_gpio = <0xffffffff 0x02 0x00>;
				sec,gpio_spi_cs = <0xffffffff 0x03 0x00>;
				sec,project_name = "sec\0universal9925";
				sec,bringup = <0x01>;
				sec,regulator_boot_on;
				sec,ss_touch_num = <0x01>;
				sec,tclm_level = <0x01>;
				sec,afe_base = <0x00>;
				sec,area-size = <0x85 0x10a 0x155>;
				sec,max_coords = <0x1000 0x1000>;
				enable_settings_aot;
				support_dex_mode;
				support_mis_calibration_test;
				support_ear_detect_mode;
				support_open_short_test;
				sec,firmware_name = "tsp_stm/fts9cu80f_q2.bin";
				sec,support_dual_foldable = <0x01>;
				phandle = <0x8f>;

				controller-data {
					samsung,spi-feedback-delay = <0x00>;
				};
			};
		};
	};

	__symbols__ {
		max77705_irq = "/fragment@0/__overlay__/max77705-irq";
		hsi2c2_bus_max77705 = "/fragment@1/__overlay__/hsi2c2-bus-max77705";
		max77705 = "/fragment@2/__overlay__/max77705@66";
		sec_battery = "/fragment@battery/__overlay__/battery";
		max77705_fuelgauge = "/fragment@battery/__overlay__/max77705-fuelgauge";
		sec_battery_cable = "/fragment@battery/__overlay__/cable-info";
		sec_battery_wireless_power_info = "/fragment@battery/__overlay__/wireless-power-info";
		wpc_en = "/fragment@3/__overlay__/wpc-en";
		dc_cpen = "/fragment@4/__overlay__/dc-cpen";
		wpc_det = "/fragment@5/__overlay__/wpc-det";
		wpc_int = "/fragment@5/__overlay__/wpc-int";
		mfc_i2c = "/fragment@6/__overlay__/mfc-i2c";
		s2mps25_gpadc = "/fragment@model/__overlay__/acpm_mfd_bus@15960000/s2mps25mfd@1f/s2mps25-gpadc";
		b1_reg = "/fragment@model/__overlay__/acpm_mfd_bus@15960000/s2mps25mfd@1f/regulators/BUCK1";
		b2_reg = "/fragment@model/__overlay__/acpm_mfd_bus@15960000/s2mps25mfd@1f/regulators/BUCK2";
		b3_reg = "/fragment@model/__overlay__/acpm_mfd_bus@15960000/s2mps25mfd@1f/regulators/BUCK3";
		b4_reg = "/fragment@model/__overlay__/acpm_mfd_bus@15960000/s2mps25mfd@1f/regulators/BUCK4";
		b5_reg = "/fragment@model/__overlay__/acpm_mfd_bus@15960000/s2mps25mfd@1f/regulators/BUCK5";
		b6_reg = "/fragment@model/__overlay__/acpm_mfd_bus@15960000/s2mps25mfd@1f/regulators/BUCK6";
		b7_reg = "/fragment@model/__overlay__/acpm_mfd_bus@15960000/s2mps25mfd@1f/regulators/BUCK7";
		b8_reg = "/fragment@model/__overlay__/acpm_mfd_bus@15960000/s2mps25mfd@1f/regulators/BUCK8";
		b9_reg = "/fragment@model/__overlay__/acpm_mfd_bus@15960000/s2mps25mfd@1f/regulators/BUCK9";
		b10_reg = "/fragment@model/__overlay__/acpm_mfd_bus@15960000/s2mps25mfd@1f/regulators/BUCK10";
		b_sr1_reg = "/fragment@model/__overlay__/acpm_mfd_bus@15960000/s2mps25mfd@1f/regulators/BUCK_SR1";
		b_sr2_reg = "/fragment@model/__overlay__/acpm_mfd_bus@15960000/s2mps25mfd@1f/regulators/BUCK_SR2";
		b_sr3_reg = "/fragment@model/__overlay__/acpm_mfd_bus@15960000/s2mps25mfd@1f/regulators/BUCK_SR3";
		l1_reg = "/fragment@model/__overlay__/acpm_mfd_bus@15960000/s2mps25mfd@1f/regulators/LDO1";
		l2_reg = "/fragment@model/__overlay__/acpm_mfd_bus@15960000/s2mps25mfd@1f/regulators/LDO2";
		l3_reg = "/fragment@model/__overlay__/acpm_mfd_bus@15960000/s2mps25mfd@1f/regulators/LDO3";
		l4_reg = "/fragment@model/__overlay__/acpm_mfd_bus@15960000/s2mps25mfd@1f/regulators/LDO4";
		l5_reg = "/fragment@model/__overlay__/acpm_mfd_bus@15960000/s2mps25mfd@1f/regulators/LDO5";
		l6_reg = "/fragment@model/__overlay__/acpm_mfd_bus@15960000/s2mps25mfd@1f/regulators/LDO6";
		l7_reg = "/fragment@model/__overlay__/acpm_mfd_bus@15960000/s2mps25mfd@1f/regulators/LDO7";
		l9_reg = "/fragment@model/__overlay__/acpm_mfd_bus@15960000/s2mps25mfd@1f/regulators/LDO9";
		l10_reg = "/fragment@model/__overlay__/acpm_mfd_bus@15960000/s2mps25mfd@1f/regulators/LDO10";
		l11_reg = "/fragment@model/__overlay__/acpm_mfd_bus@15960000/s2mps25mfd@1f/regulators/LDO11";
		l12_reg = "/fragment@model/__overlay__/acpm_mfd_bus@15960000/s2mps25mfd@1f/regulators/LDO12";
		l13_reg = "/fragment@model/__overlay__/acpm_mfd_bus@15960000/s2mps25mfd@1f/regulators/LDO13";
		l14_reg = "/fragment@model/__overlay__/acpm_mfd_bus@15960000/s2mps25mfd@1f/regulators/LDO14";
		l15_reg = "/fragment@model/__overlay__/acpm_mfd_bus@15960000/s2mps25mfd@1f/regulators/LDO15";
		l16_reg = "/fragment@model/__overlay__/acpm_mfd_bus@15960000/s2mps25mfd@1f/regulators/LDO16";
		l17_reg = "/fragment@model/__overlay__/acpm_mfd_bus@15960000/s2mps25mfd@1f/regulators/LDO17";
		l18_reg = "/fragment@model/__overlay__/acpm_mfd_bus@15960000/s2mps25mfd@1f/regulators/LDO18";
		l19_reg = "/fragment@model/__overlay__/acpm_mfd_bus@15960000/s2mps25mfd@1f/regulators/LDO19";
		l20_reg = "/fragment@model/__overlay__/acpm_mfd_bus@15960000/s2mps25mfd@1f/regulators/LDO20";
		l21_reg = "/fragment@model/__overlay__/acpm_mfd_bus@15960000/s2mps25mfd@1f/regulators/LDO21";
		l22_reg = "/fragment@model/__overlay__/acpm_mfd_bus@15960000/s2mps25mfd@1f/regulators/LDO22";
		l23_reg = "/fragment@model/__overlay__/acpm_mfd_bus@15960000/s2mps25mfd@1f/regulators/LDO23";
		l24_reg = "/fragment@model/__overlay__/acpm_mfd_bus@15960000/s2mps25mfd@1f/regulators/LDO24";
		l25_reg = "/fragment@model/__overlay__/acpm_mfd_bus@15960000/s2mps25mfd@1f/regulators/LDO25";
		l26_reg = "/fragment@model/__overlay__/acpm_mfd_bus@15960000/s2mps25mfd@1f/regulators/LDO26";
		l27_reg = "/fragment@model/__overlay__/acpm_mfd_bus@15960000/s2mps25mfd@1f/regulators/LDO27";
		l28_reg = "/fragment@model/__overlay__/acpm_mfd_bus@15960000/s2mps25mfd@1f/regulators/LDO28";
		l29_reg = "/fragment@model/__overlay__/acpm_mfd_bus@15960000/s2mps25mfd@1f/regulators/LDO29";
		l30_reg = "/fragment@model/__overlay__/acpm_mfd_bus@15960000/s2mps25mfd@1f/regulators/LDO30";
		s2mps26_gpio = "/fragment@model/__overlay__/acpm_mfd_bus@15961000/s2mps26mfd@2f/s2mps26-gpio";
		s_b1_reg = "/fragment@model/__overlay__/acpm_mfd_bus@15961000/s2mps26mfd@2f/regulators/BUCK1";
		s_b2_reg = "/fragment@model/__overlay__/acpm_mfd_bus@15961000/s2mps26mfd@2f/regulators/BUCK2";
		s_b3_reg = "/fragment@model/__overlay__/acpm_mfd_bus@15961000/s2mps26mfd@2f/regulators/BUCK3";
		s_b4_reg = "/fragment@model/__overlay__/acpm_mfd_bus@15961000/s2mps26mfd@2f/regulators/BUCK4";
		s_b5_reg = "/fragment@model/__overlay__/acpm_mfd_bus@15961000/s2mps26mfd@2f/regulators/BUCK5";
		s_b6_reg = "/fragment@model/__overlay__/acpm_mfd_bus@15961000/s2mps26mfd@2f/regulators/BUCK6";
		s_b7_reg = "/fragment@model/__overlay__/acpm_mfd_bus@15961000/s2mps26mfd@2f/regulators/BUCK7";
		s_b_sr1_reg = "/fragment@model/__overlay__/acpm_mfd_bus@15961000/s2mps26mfd@2f/regulators/BUCK_SR1";
		s_bb_reg = "/fragment@model/__overlay__/acpm_mfd_bus@15961000/s2mps26mfd@2f/regulators/BUCKB";
		s_l1_reg = "/fragment@model/__overlay__/acpm_mfd_bus@15961000/s2mps26mfd@2f/regulators/LDO1";
		s_l3_reg = "/fragment@model/__overlay__/acpm_mfd_bus@15961000/s2mps26mfd@2f/regulators/LDO3";
		s_l4_reg = "/fragment@model/__overlay__/acpm_mfd_bus@15961000/s2mps26mfd@2f/regulators/LDO4";
		s_l6_reg = "/fragment@model/__overlay__/acpm_mfd_bus@15961000/s2mps26mfd@2f/regulators/LDO6";
		s_l7_reg = "/fragment@model/__overlay__/acpm_mfd_bus@15961000/s2mps26mfd@2f/regulators/LDO7";
		s_l8_reg = "/fragment@model/__overlay__/acpm_mfd_bus@15961000/s2mps26mfd@2f/regulators/LDO8";
		s_l9_reg = "/fragment@model/__overlay__/acpm_mfd_bus@15961000/s2mps26mfd@2f/regulators/LDO9";
		s_l14_reg = "/fragment@model/__overlay__/acpm_mfd_bus@15961000/s2mps26mfd@2f/regulators/LDO14";
		s_l15_reg = "/fragment@model/__overlay__/acpm_mfd_bus@15961000/s2mps26mfd@2f/regulators/LDO15";
		s_l16_reg = "/fragment@model/__overlay__/acpm_mfd_bus@15961000/s2mps26mfd@2f/regulators/LDO16";
		s_l17_reg = "/fragment@model/__overlay__/acpm_mfd_bus@15961000/s2mps26mfd@2f/regulators/LDO17";
		s_l18_reg = "/fragment@model/__overlay__/acpm_mfd_bus@15961000/s2mps26mfd@2f/regulators/LDO18";
		s_l19_reg = "/fragment@model/__overlay__/acpm_mfd_bus@15961000/s2mps26mfd@2f/regulators/LDO19";
		s_l20_reg = "/fragment@model/__overlay__/acpm_mfd_bus@15961000/s2mps26mfd@2f/regulators/LDO20";
		s2mpm07_gpio = "/fragment@model/__overlay__/acpm_mfd_bus@15962000/s2mpm07mfd@3f/s2mpm07-gpio";
		r_b1_reg = "/fragment@model/__overlay__/acpm_mfd_bus@15962000/s2mpm07mfd@3f/regulators/BUCK1";
		r_l11_reg = "/fragment@model/__overlay__/acpm_mfd_bus@15962000/s2mpm07mfd@3f/regulators/LDO11";
		r_l18_reg = "/fragment@model/__overlay__/acpm_mfd_bus@15962000/s2mpm07mfd@3f/regulators/LDO18";
		r_l19_reg = "/fragment@model/__overlay__/acpm_mfd_bus@15962000/s2mpm07mfd@3f/regulators/LDO19";
		eusb_repeater_tune = "/fragment@model/__overlay__/hs_tune";
		usb_ss_tune = "/fragment@model/__overlay__/ss_tune";
		vbat = "/fragment@model/__overlay__/vbat";
		dummy_audio_codec = "/fragment@model/__overlay__/audio-codec-dummy";
		dummy_audio_cpu = "/fragment@model/__overlay__/audio-cpu-dummy";
		key_volup = "/fragment@10/__overlay__/key-volup";
		tsp_int_active = "/fragment@10/__overlay__/tsp_int_active";
		tsp_int_sleep = "/fragment@10/__overlay__/tsp_int_sleep";
		eusb_ctrl = "/fragment@10/__overlay__/eusb_ctrl_sel";
		pm_wrstbi = "/fragment@11/__overlay__/pm-wrstbi";
		sub_pmic_irq = "/fragment@12/__overlay__/sub-pmic-irq";
		smpl_warn = "/fragment@13/__overlay__/smpl-warn";
		ext_bin_0 = "/fragment@14/__overlay__/ext-bin@0";
		ext_bin_1 = "/fragment@14/__overlay__/ext-bin@1";
		ext_bin_2 = "/fragment@14/__overlay__/ext-bin@2";
		ext_bin_3 = "/fragment@14/__overlay__/ext-bin@3";
		ext_bin_4 = "/fragment@14/__overlay__/ext-bin@4";
		ext_bin_5 = "/fragment@14/__overlay__/ext-bin@5";
		ext_bin_6 = "/fragment@14/__overlay__/ext-bin@6";
		ext_bin_7 = "/fragment@14/__overlay__/ext-bin@7";
		ext_bin_8 = "/fragment@14/__overlay__/ext-bin@8";
		ext_bin_9 = "/fragment@14/__overlay__/ext-bin@9";
		ext_bin_10 = "/fragment@14/__overlay__/ext-bin@10";
		ext_bin_11 = "/fragment@14/__overlay__/ext-bin@11";
		ext_bin_12 = "/fragment@14/__overlay__/ext-bin@12";
		ext_bin_13 = "/fragment@14/__overlay__/ext-bin@13";
		ext_bin_14 = "/fragment@14/__overlay__/ext-bin@14";
		ext_bin_15 = "/fragment@14/__overlay__/ext-bin@15";
		ext_bin_16 = "/fragment@14/__overlay__/ext-bin@16";
		ext_bin_17 = "/fragment@14/__overlay__/ext-bin@17";
		cs35l41_r_reset = "/fragment@16/__overlay__/cs35l41-r-reset";
		cs35l41_l_reset = "/fragment@16/__overlay__/cs35l41-l-reset";
		cs35l41_r = "/fragment@17/__overlay__/cs35l41@40";
		cs35l41_l = "/fragment@17/__overlay__/cs35l41@41";
		_buck1_reg = "/fragment@18/__overlay__/s2mpb02_pmic@59/regulators/s2mpb02-buck1";
		_buck2_reg = "/fragment@18/__overlay__/s2mpb02_pmic@59/regulators/s2mpb02-buck2";
		_buckboost_reg = "/fragment@18/__overlay__/s2mpb02_pmic@59/regulators/s2mpb02-bb";
		_ldo1_reg = "/fragment@18/__overlay__/s2mpb02_pmic@59/regulators/s2mpb02-ldo1";
		_ldo2_reg = "/fragment@18/__overlay__/s2mpb02_pmic@59/regulators/s2mpb02-ldo2";
		_ldo3_reg = "/fragment@18/__overlay__/s2mpb02_pmic@59/regulators/s2mpb02-ldo3";
		_ldo4_reg = "/fragment@18/__overlay__/s2mpb02_pmic@59/regulators/s2mpb02-ldo4";
		_ldo5_reg = "/fragment@18/__overlay__/s2mpb02_pmic@59/regulators/s2mpb02-ldo5";
		_ldo6_reg = "/fragment@18/__overlay__/s2mpb02_pmic@59/regulators/s2mpb02-ldo6";
		_ldo7_reg = "/fragment@18/__overlay__/s2mpb02_pmic@59/regulators/s2mpb02-ldo7";
		_ldo8_reg = "/fragment@18/__overlay__/s2mpb02_pmic@59/regulators/s2mpb02-ldo8";
		_ldo9_reg = "/fragment@18/__overlay__/s2mpb02_pmic@59/regulators/s2mpb02-ldo9";
		_ldo10_reg = "/fragment@18/__overlay__/s2mpb02_pmic@59/regulators/s2mpb02-ldo10";
		_ldo11_reg = "/fragment@18/__overlay__/s2mpb02_pmic@59/regulators/s2mpb02-ldo11";
		_ldo12_reg = "/fragment@18/__overlay__/s2mpb02_pmic@59/regulators/s2mpb02-ldo12";
		_ldo13_reg = "/fragment@18/__overlay__/s2mpb02_pmic@59/regulators/s2mpb02-ldo13";
		_ldo14_reg = "/fragment@18/__overlay__/s2mpb02_pmic@59/regulators/s2mpb02-ldo14";
		_ldo15_reg = "/fragment@18/__overlay__/s2mpb02_pmic@59/regulators/s2mpb02-ldo15";
		_ldo16_reg = "/fragment@18/__overlay__/s2mpb02_pmic@59/regulators/s2mpb02-ldo16";
		_ldo17_reg = "/fragment@18/__overlay__/s2mpb02_pmic@59/regulators/s2mpb02-ldo17";
		_ldo18_reg = "/fragment@18/__overlay__/s2mpb02_pmic@59/regulators/s2mpb02-ldo18";
		drmpanel0 = "/fragment@22/__overlay__/drmpanel";
		samsung_emulation_video_panel = "/fragment@22/__overlay__/drmpanel/samsung_emulation_video_panel";
		s6e3fac_1080_2340_cmd = "/fragment@22/__overlay__/drmpanel/s6e3fac_1080_2340_cmd";
		tsp_stm_spi = "/fragment@25/__overlay__/touchscreen@0";
	};

	__fixups__ {
		pinctrl_0 = "/fragment@0:target:0\0/fragment@3:target:0\0/fragment@5:target:0\0/fragment@10:target:0";
		pinctrl_1 = "/fragment@1:target:0\0/fragment@4:target:0\0/fragment@11:target:0";
		hsi2c_24 = "/fragment@2:target:0";
		gpa0 = "/fragment@2/__overlay__/max77705@66:max77705,irq-gpio:0";
		gpa2 = "/fragment@battery/__overlay__/battery:battery,wpc_det:0";
		gpa3 = "/fragment@battery/__overlay__/battery:battery,wpc_int:0\0/fragment@battery/__overlay__/max77705-fuelgauge:fuelgauge,jig_gpio:0\0/fragment@7/__overlay__/mfc-charger@3b:battery,wpc_int:0\0/fragment@model/__overlay__/gpio_keys/button@3:gpios:0";
		pinctrl_7 = "/fragment@6:target:0\0/fragment@13:target:0";
		hsi2c_32 = "/fragment@7:target:0";
		gpa1 = "/fragment@7/__overlay__/mfc-charger@3b:battery,wpc_det:0\0/fragment@17/__overlay__/cs35l41@40:interrupt-parent:0\0/fragment@17/__overlay__/cs35l41@41:interrupt-parent:0\0/fragment@25/__overlay__/touchscreen@0:sec,irq_gpio:0";
		gpm10 = "/fragment@7/__overlay__/mfc-charger@3b:battery,mst_pwr_en:0";
		dsim_modes = "/fragment@8:target:0\0/fragment@22/__overlay__/drmpanel:dsim_mode:0";
		gic = "/fragment@model/__overlay__/acpm_mfd_bus@15960000/s2mps25mfd@1f:interrupt-parent:0";
		gpg0 = "/fragment@model/__overlay__/acpm_mfd_bus@15960000/s2mps25mfd@1f:gpios:0";
		udc = "/fragment@model/__overlay__/usb_notifier:udc:0\0/fragment@19:target:0";
		clock = "/fragment@model/__overlay__/sound:clocks:0";
		dp_dma0 = "/fragment@model/__overlay__/sound:dmas:0\0/fragment@model/__overlay__/sound/dp0_audio/platform:sound-dai:0";
		dp_dma1 = "/fragment@model/__overlay__/sound:dmas:4\0/fragment@model/__overlay__/sound/dp1_audio/platform:sound-dai:0";
		abox_effect = "/fragment@model/__overlay__/sound:samsung,aux:0";
		abox_tplg = "/fragment@model/__overlay__/sound:samsung,aux:4";
		abox_rdma_0 = "/fragment@model/__overlay__/sound/rdma0/cpu:sound-dai:0\0/fragment@model/__overlay__/sound/rdma0/platform:sound-dai:0\0/fragment@model/__overlay__/sound/rdma0_be/cpu:sound-dai:0\0/fragment@model/__overlay__/sound/rdma0_be/platform:sound-dai:0";
		abox_rdma_1 = "/fragment@model/__overlay__/sound/rdma1/cpu:sound-dai:0\0/fragment@model/__overlay__/sound/rdma1/platform:sound-dai:0\0/fragment@model/__overlay__/sound/rdma1_be/cpu:sound-dai:0\0/fragment@model/__overlay__/sound/rdma1_be/platform:sound-dai:0";
		abox_rdma_2 = "/fragment@model/__overlay__/sound/rdma2/cpu:sound-dai:0\0/fragment@model/__overlay__/sound/rdma2/platform:sound-dai:0\0/fragment@model/__overlay__/sound/rdma2_be/cpu:sound-dai:0\0/fragment@model/__overlay__/sound/rdma2_be/platform:sound-dai:0";
		abox_rdma_3 = "/fragment@model/__overlay__/sound/rdma3/cpu:sound-dai:0\0/fragment@model/__overlay__/sound/rdma3/platform:sound-dai:0\0/fragment@model/__overlay__/sound/rdma3_be/cpu:sound-dai:0\0/fragment@model/__overlay__/sound/rdma3_be/platform:sound-dai:0";
		abox_rdma_4 = "/fragment@model/__overlay__/sound/rdma4/cpu:sound-dai:0\0/fragment@model/__overlay__/sound/rdma4/platform:sound-dai:0\0/fragment@model/__overlay__/sound/rdma4_be/cpu:sound-dai:0\0/fragment@model/__overlay__/sound/rdma4_be/platform:sound-dai:0";
		abox_rdma_5 = "/fragment@model/__overlay__/sound/rdma5/cpu:sound-dai:0\0/fragment@model/__overlay__/sound/rdma5/platform:sound-dai:0\0/fragment@model/__overlay__/sound/rdma5_be/cpu:sound-dai:0\0/fragment@model/__overlay__/sound/rdma5_be/platform:sound-dai:0";
		abox_rdma_6 = "/fragment@model/__overlay__/sound/rdma6/cpu:sound-dai:0\0/fragment@model/__overlay__/sound/rdma6/platform:sound-dai:0\0/fragment@model/__overlay__/sound/rdma6_be/cpu:sound-dai:0\0/fragment@model/__overlay__/sound/rdma6_be/platform:sound-dai:0";
		abox_rdma_7 = "/fragment@model/__overlay__/sound/rdma7/cpu:sound-dai:0\0/fragment@model/__overlay__/sound/rdma7/platform:sound-dai:0\0/fragment@model/__overlay__/sound/rdma7_be/cpu:sound-dai:0\0/fragment@model/__overlay__/sound/rdma7_be/platform:sound-dai:0";
		abox_rdma_8 = "/fragment@model/__overlay__/sound/rdma8/cpu:sound-dai:0\0/fragment@model/__overlay__/sound/rdma8/platform:sound-dai:0\0/fragment@model/__overlay__/sound/rdma8_be/cpu:sound-dai:0\0/fragment@model/__overlay__/sound/rdma8_be/platform:sound-dai:0";
		abox_rdma_9 = "/fragment@model/__overlay__/sound/rdma9/cpu:sound-dai:0\0/fragment@model/__overlay__/sound/rdma9/platform:sound-dai:0\0/fragment@model/__overlay__/sound/rdma9_be/cpu:sound-dai:0\0/fragment@model/__overlay__/sound/rdma9_be/platform:sound-dai:0";
		abox_rdma_10 = "/fragment@model/__overlay__/sound/rdma10/cpu:sound-dai:0\0/fragment@model/__overlay__/sound/rdma10/platform:sound-dai:0\0/fragment@model/__overlay__/sound/rdma10_be/cpu:sound-dai:0\0/fragment@model/__overlay__/sound/rdma10_be/platform:sound-dai:0";
		abox_rdma_11 = "/fragment@model/__overlay__/sound/rdma11/cpu:sound-dai:0\0/fragment@model/__overlay__/sound/rdma11/platform:sound-dai:0\0/fragment@model/__overlay__/sound/rdma11_be/cpu:sound-dai:0\0/fragment@model/__overlay__/sound/rdma11_be/platform:sound-dai:0";
		abox_wdma_0 = "/fragment@model/__overlay__/sound/wdma0/cpu:sound-dai:0\0/fragment@model/__overlay__/sound/wdma0/platform:sound-dai:0\0/fragment@model/__overlay__/sound/wdma0_be/cpu:sound-dai:0\0/fragment@model/__overlay__/sound/wdma0_be/platform:sound-dai:0";
		abox_wdma_1 = "/fragment@model/__overlay__/sound/wdma1/cpu:sound-dai:0\0/fragment@model/__overlay__/sound/wdma1/platform:sound-dai:0\0/fragment@model/__overlay__/sound/wdma1_be/cpu:sound-dai:0\0/fragment@model/__overlay__/sound/wdma1_be/platform:sound-dai:0";
		abox_wdma_2 = "/fragment@model/__overlay__/sound/wdma2/cpu:sound-dai:0\0/fragment@model/__overlay__/sound/wdma2/platform:sound-dai:0\0/fragment@model/__overlay__/sound/wdma2_be/cpu:sound-dai:0\0/fragment@model/__overlay__/sound/wdma2_be/platform:sound-dai:0";
		abox_wdma_3 = "/fragment@model/__overlay__/sound/wdma3/cpu:sound-dai:0\0/fragment@model/__overlay__/sound/wdma3/platform:sound-dai:0\0/fragment@model/__overlay__/sound/wdma3_be/cpu:sound-dai:0\0/fragment@model/__overlay__/sound/wdma3_be/platform:sound-dai:0";
		abox_wdma_4 = "/fragment@model/__overlay__/sound/wdma4/cpu:sound-dai:0\0/fragment@model/__overlay__/sound/wdma4/platform:sound-dai:0\0/fragment@model/__overlay__/sound/wdma4_be/cpu:sound-dai:0\0/fragment@model/__overlay__/sound/wdma4_be/platform:sound-dai:0";
		abox_wdma_5 = "/fragment@model/__overlay__/sound/wdma5/cpu:sound-dai:0\0/fragment@model/__overlay__/sound/wdma5/platform:sound-dai:0\0/fragment@model/__overlay__/sound/wdma5_be/cpu:sound-dai:0\0/fragment@model/__overlay__/sound/wdma5_be/platform:sound-dai:0";
		abox_wdma_6 = "/fragment@model/__overlay__/sound/wdma6/cpu:sound-dai:0\0/fragment@model/__overlay__/sound/wdma6/platform:sound-dai:0\0/fragment@model/__overlay__/sound/wdma6_be/cpu:sound-dai:0\0/fragment@model/__overlay__/sound/wdma6_be/platform:sound-dai:0";
		abox_wdma_7 = "/fragment@model/__overlay__/sound/wdma7/cpu:sound-dai:0\0/fragment@model/__overlay__/sound/wdma7/platform:sound-dai:0\0/fragment@model/__overlay__/sound/wdma7_be/cpu:sound-dai:0\0/fragment@model/__overlay__/sound/wdma7_be/platform:sound-dai:0";
		abox_wdma_8 = "/fragment@model/__overlay__/sound/wdma8/cpu:sound-dai:0\0/fragment@model/__overlay__/sound/wdma8/platform:sound-dai:0\0/fragment@model/__overlay__/sound/wdma8_be/cpu:sound-dai:0\0/fragment@model/__overlay__/sound/wdma8_be/platform:sound-dai:0";
		abox_wdma_9 = "/fragment@model/__overlay__/sound/wdma9/cpu:sound-dai:0\0/fragment@model/__overlay__/sound/wdma9/platform:sound-dai:0\0/fragment@model/__overlay__/sound/wdma9_be/cpu:sound-dai:0\0/fragment@model/__overlay__/sound/wdma9_be/platform:sound-dai:0";
		abox_wdma_10 = "/fragment@model/__overlay__/sound/wdma10/cpu:sound-dai:0\0/fragment@model/__overlay__/sound/wdma10/platform:sound-dai:0\0/fragment@model/__overlay__/sound/wdma10_be/cpu:sound-dai:0\0/fragment@model/__overlay__/sound/wdma10_be/platform:sound-dai:0";
		abox_wdma_11 = "/fragment@model/__overlay__/sound/wdma11/cpu:sound-dai:0\0/fragment@model/__overlay__/sound/wdma11/platform:sound-dai:0\0/fragment@model/__overlay__/sound/wdma11_be/cpu:sound-dai:0\0/fragment@model/__overlay__/sound/wdma11_be/platform:sound-dai:0";
		vts = "/fragment@model/__overlay__/sound/vts0/cpu:sound-dai:0\0/fragment@model/__overlay__/sound/vts1/cpu:sound-dai:0";
		vts_dma0 = "/fragment@model/__overlay__/sound/vts0/platform:sound-dai:0";
		vts_dma1 = "/fragment@model/__overlay__/sound/vts1/platform:sound-dai:0";
		displayport_adma = "/fragment@model/__overlay__/sound/dp0_audio/cpu:sound-dai:0\0/fragment@model/__overlay__/sound/dp1_audio/cpu:sound-dai:0";
		abox_dual_0 = "/fragment@model/__overlay__/sound/dual0/cpu:sound-dai:0\0/fragment@model/__overlay__/sound/dual0/platform:sound-dai:0";
		abox_dual_1 = "/fragment@model/__overlay__/sound/dual1/cpu:sound-dai:0\0/fragment@model/__overlay__/sound/dual1/platform:sound-dai:0";
		abox_dual_2 = "/fragment@model/__overlay__/sound/dual2/cpu:sound-dai:0\0/fragment@model/__overlay__/sound/dual2/platform:sound-dai:0";
		abox_dual_3 = "/fragment@model/__overlay__/sound/dual3/cpu:sound-dai:0\0/fragment@model/__overlay__/sound/dual3/platform:sound-dai:0";
		abox_dual_4 = "/fragment@model/__overlay__/sound/dual4/cpu:sound-dai:0\0/fragment@model/__overlay__/sound/dual4/platform:sound-dai:0";
		abox_dual_5 = "/fragment@model/__overlay__/sound/dual5/cpu:sound-dai:0\0/fragment@model/__overlay__/sound/dual5/platform:sound-dai:0";
		abox_dual_6 = "/fragment@model/__overlay__/sound/dual6/cpu:sound-dai:0\0/fragment@model/__overlay__/sound/dual6/platform:sound-dai:0";
		abox_dual_7 = "/fragment@model/__overlay__/sound/dual7/cpu:sound-dai:0\0/fragment@model/__overlay__/sound/dual7/platform:sound-dai:0";
		abox_dual_8 = "/fragment@model/__overlay__/sound/dual8/cpu:sound-dai:0\0/fragment@model/__overlay__/sound/dual8/platform:sound-dai:0";
		abox_dual_9 = "/fragment@model/__overlay__/sound/dual9/cpu:sound-dai:0\0/fragment@model/__overlay__/sound/dual9/platform:sound-dai:0";
		abox_dual_10 = "/fragment@model/__overlay__/sound/dual10/cpu:sound-dai:0\0/fragment@model/__overlay__/sound/dual10/platform:sound-dai:0";
		abox_dual_11 = "/fragment@model/__overlay__/sound/dual11/cpu:sound-dai:0\0/fragment@model/__overlay__/sound/dual11/platform:sound-dai:0";
		abox_ddma_0 = "/fragment@model/__overlay__/sound/ddma0/cpu:sound-dai:0\0/fragment@model/__overlay__/sound/ddma0/platform:sound-dai:0";
		abox_ddma_1 = "/fragment@model/__overlay__/sound/ddma1/cpu:sound-dai:0\0/fragment@model/__overlay__/sound/ddma1/platform:sound-dai:0";
		abox_ddma_2 = "/fragment@model/__overlay__/sound/ddma2/cpu:sound-dai:0\0/fragment@model/__overlay__/sound/ddma2/platform:sound-dai:0";
		abox_ddma_3 = "/fragment@model/__overlay__/sound/ddma3/cpu:sound-dai:0\0/fragment@model/__overlay__/sound/ddma3/platform:sound-dai:0";
		abox_ddma_4 = "/fragment@model/__overlay__/sound/ddma4/cpu:sound-dai:0\0/fragment@model/__overlay__/sound/ddma4/platform:sound-dai:0";
		abox_ddma_5 = "/fragment@model/__overlay__/sound/ddma5/cpu:sound-dai:0\0/fragment@model/__overlay__/sound/ddma5/platform:sound-dai:0";
		abox_uaif_0 = "/fragment@model/__overlay__/sound/uaif0/cpu:sound-dai:0";
		abox_uaif_1 = "/fragment@model/__overlay__/sound/uaif1/cpu:sound-dai:0";
		abox_uaif_2 = "/fragment@model/__overlay__/sound/uaif2/cpu:sound-dai:0";
		abox_uaif_3 = "/fragment@model/__overlay__/sound/uaif3/cpu:sound-dai:0\0/fragment@15:target:0";
		abox_uaif_4 = "/fragment@model/__overlay__/sound/uaif4/cpu:sound-dai:0";
		abox_uaif_5 = "/fragment@model/__overlay__/sound/uaif5/cpu:sound-dai:0";
		abox_uaif_6 = "/fragment@model/__overlay__/sound/uaif6/cpu:sound-dai:0";
		vts_s_lif = "/fragment@model/__overlay__/sound/uaif6/codec:sound-dai:0";
		abox_dsif = "/fragment@model/__overlay__/sound/dsif0/cpu:sound-dai:0";
		abox_udma_rd_0 = "/fragment@model/__overlay__/sound/udma_rd0/cpu:sound-dai:0";
		abox_udma_rd_1 = "/fragment@model/__overlay__/sound/udma_rd1/cpu:sound-dai:0";
		abox_udma_wr_0 = "/fragment@model/__overlay__/sound/udma_wr0/cpu:sound-dai:0";
		abox_udma_wr_1 = "/fragment@model/__overlay__/sound/udma_wr1/cpu:sound-dai:0";
		abox_udma_wr_dual_0 = "/fragment@model/__overlay__/sound/udma_wr_dual0/cpu:sound-dai:0";
		abox_udma_wr_dual_1 = "/fragment@model/__overlay__/sound/udma_wr_dual1/cpu:sound-dai:0";
		abox_udma_wr_debug_0 = "/fragment@model/__overlay__/sound/udma_wr_dbg0/cpu:sound-dai:0";
		abox = "/fragment@model/__overlay__/sound/usb/cpu:sound-dai:0\0/fragment@model/__overlay__/sound/fwd/cpu:sound-dai:0\0/fragment@14:target:0\0/fragment@20/__overlay__:abox:0";
		serial_0 = "/fragment@9:target:0";
		pinctrl_6 = "/fragment@12:target:0";
		pinctrl_5 = "/fragment@16:target:0";
		hsi2c_21 = "/fragment@17:target:0";
		gpb3 = "/fragment@17/__overlay__/cs35l41@40:reset-gpios:0\0/fragment@17/__overlay__/cs35l41@41:reset-gpios:0";
		i3c_2 = "/fragment@18:target:0";
		usbdrd_dwc3 = "/fragment@20:target:0";
		usbdrd_phy0 = "/fragment@21:target:0";
		gpc7 = "/fragment@21/__overlay__:phy,gpio_phy_port:0\0/fragment@22/__overlay__/drmpanel:reset-gpios:0\0/fragment@23/__overlay__:dp,usb_con_sel:0";
		drmdsim_0 = "/fragment@22:target:0";
		ddi_rst = "/fragment@22/__overlay__/drmpanel:pinctrl-0:0";
		drmdp = "/fragment@23:target:0";
		ufs = "/fragment@24:target:0";
		spi_2 = "/fragment@25:target:0";
		gpp2 = "/fragment@25/__overlay__/touchscreen@0:sec,gpio_spi_cs:0";
	};

	__local_fixups__ {

		fragment@2 {

			__overlay__ {
				pinctrl-0 = <0x00>;

				max77705@66 {
					pinctrl-0 = <0x00>;
				};
			};
		};

		fragment@7 {

			__overlay__ {

				mfc-charger@3b {
					pinctrl-0 = <0x00 0x04>;
				};
			};
		};

		fragment@model {

			__overlay__ {

				gpio_keys {
					pinctrl-0 = <0x00>;
				};

				acpm_mfd_bus@15960000 {

					s2mps25mfd@1f {
						pinctrl-0 = <0x00 0x04>;
					};
				};

				sound {
					MICBIAS1-supply = <0x00>;
					MICBIAS2-supply = <0x00>;
					MICBIAS3-supply = <0x00>;
					samsung,codec = <0x00 0x04>;

					uaif1 {

						codec {
							sound-dai = <0x00 0x08>;
						};
					};
				};
			};
		};

		fragment@17 {

			__overlay__ {

				cs35l41@40 {
					pinctrl-0 = <0x00>;
					VA-supply = <0x00>;
					VP-supply = <0x00>;
				};

				cs35l41@41 {
					pinctrl-0 = <0x00>;
					VA-supply = <0x00>;
					VP-supply = <0x00>;
				};
			};
		};

		fragment@18 {

			__overlay__ {

				s2mpb02_pmic@59 {
					pinctrl-0 = <0x00>;
				};
			};
		};

		fragment@20 {

			__overlay__ {
				vdd_ldo5-supply = <0x00>;
				vdd_ldo7-supply = <0x00>;
				vdd_ldo20-supply = <0x00>;
				vdd_ldo16s-supply = <0x00>;
			};
		};

		fragment@21 {

			__overlay__ {
				hs_tune_param = <0x00>;
				ss_tune_param = <0x00>;
				vdd_ldo5-supply = <0x00>;
				vdd_ldo7-supply = <0x00>;
				vdd_ldo20-supply = <0x00>;
				vdd_ldo16s-supply = <0x00>;
			};
		};

		fragment@23 {

			__overlay__ {
				dp,aux_sw_oe = <0x00>;
				dp,sbu_sw_sel = <0x00>;
			};
		};

		fragment@24 {

			__overlay__ {
				vcc-supply = <0x00>;
				vccq-supply = <0x00>;
			};
		};

		fragment@25 {

			__overlay__ {

				touchscreen@0 {
					pinctrl-0 = <0x00>;
					pinctrl-1 = <0x00>;
					tsp_io_ldo-supply = <0x00>;
					tsp_avdd_ldo-supply = <0x00>;
				};
			};
		};
	};
};
